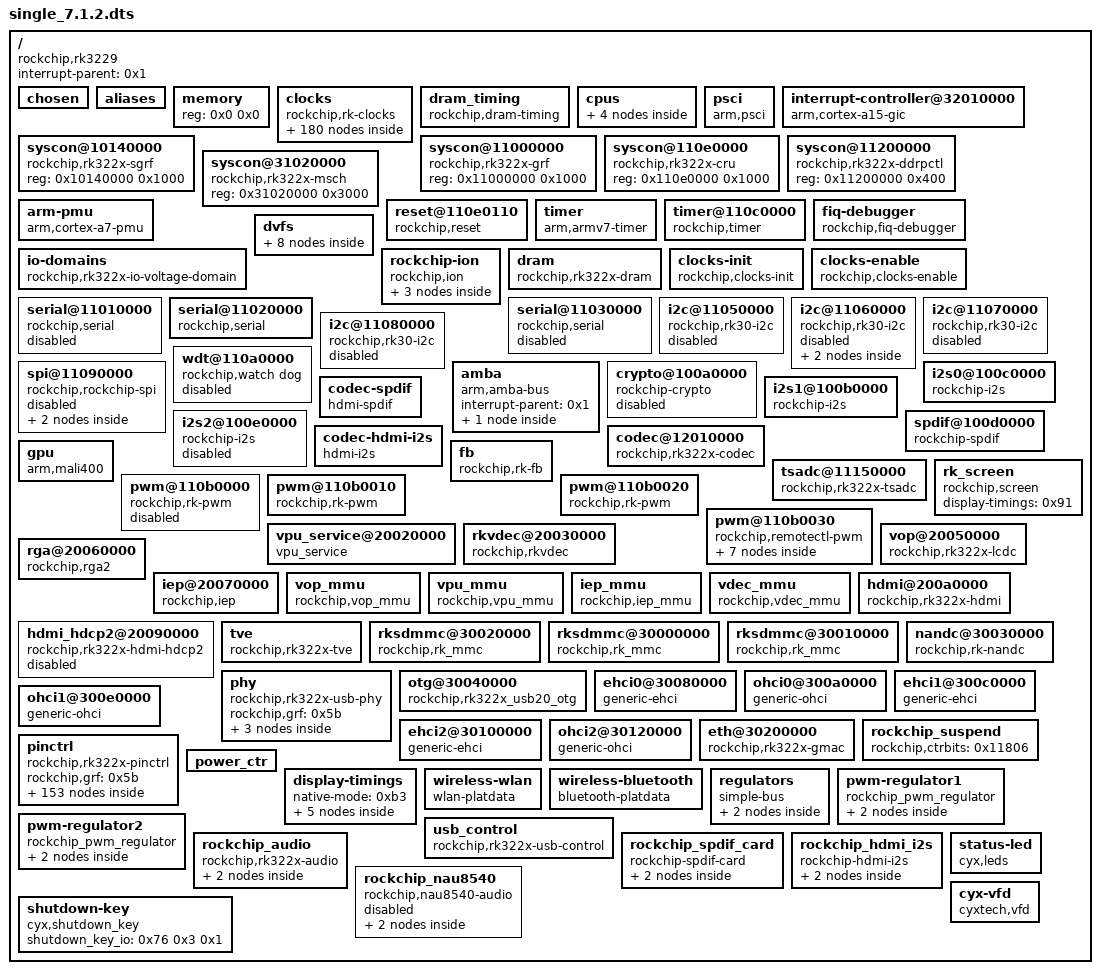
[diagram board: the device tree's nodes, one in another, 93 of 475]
/dts-v1/;

/ {
	#address-cells = <0x1>;
	#size-cells = <0x1>;
	compatible = "rockchip,rk3229";
	interrupt-parent = <0x1>;

	chosen {
		bootargs = "vmalloc=496M psci=enable rockchip_jtag";
	};

	aliases {
		serial0 = "/serial@11010000";
		serial1 = "/serial@11020000";
		serial2 = "/serial@11030000";
		i2c0 = "/i2c@11050000";
		i2c1 = "/i2c@11060000";
		i2c2 = "/i2c@11070000";
		i2c3 = "/i2c@11080000";
		lcdc0 = "/vop@20050000";
		spi0 = "/spi@11090000";
	};

	memory {
		device_type = "memory";
		reg = <0x0 0x0>;
	};

	clocks {
		compatible = "rockchip,rk-clocks";
		#address-cells = <0x1>;
		#size-cells = <0x1>;
		ranges = <0x0 0x110e0000 0x1000>;

		fixed_rate_cons {
			compatible = "rockchip,rk-fixed-rate-cons";

			xin24m {
				compatible = "rockchip,rk-fixed-clock";
				clock-output-names = "xin24m";
				clock-frequency = <0x16e3600>;
				#clock-cells = <0x0>;
				linux,phandle = <0x2>;
				phandle = <0x2>;
			};

			xin12m {
				compatible = "rockchip,rk-fixed-clock";
				clocks = <0x2>;
				clock-output-names = "xin12m";
				clock-frequency = <0xb71b00>;
				#clock-cells = <0x0>;
				linux,phandle = <0x14>;
				phandle = <0x14>;
			};

			hdmiphy_out {
				compatible = "rockchip,rk-fixed-clock";
				clock-output-names = "hdmiphy_out";
				clock-frequency = <0x2367b880>;
				#clock-cells = <0x0>;
				linux,phandle = <0x45>;
				phandle = <0x45>;
			};

			usbphy0_480m {
				compatible = "rockchip,rk-fixed-clock";
				clock-output-names = "usbphy0_480m";
				clock-frequency = <0x1c9c3800>;
				#clock-cells = <0x0>;
				linux,phandle = <0x46>;
				phandle = <0x46>;
			};

			usbphy1_480m {
				compatible = "rockchip,rk-fixed-clock";
				clock-output-names = "usbphy1_480m";
				clock-frequency = <0x1c9c3800>;
				#clock-cells = <0x0>;
				linux,phandle = <0x47>;
				phandle = <0x47>;
			};

			jtag_clkin {
				compatible = "rockchip,rk-fixed-clock";
				clock-output-names = "jtag_clkin";
				clock-frequency = <0x0>;
				#clock-cells = <0x0>;
				linux,phandle = <0x4c>;
				phandle = <0x4c>;
			};

			dummy {
				compatible = "rockchip,rk-fixed-clock";
				clock-output-names = "dummy";
				clock-frequency = <0x0>;
				#clock-cells = <0x0>;
				linux,phandle = <0x38>;
				phandle = <0x38>;
			};

			gmac_clkin {
				compatible = "rockchip,rk-fixed-clock";
				clock-output-names = "gmac_clkin";
				clock-frequency = <0x7735940>;
				#clock-cells = <0x0>;
				linux,phandle = <0x3c>;
				phandle = <0x3c>;
			};

			phy_50m_out {
				compatible = "rockchip,rk-fixed-clock";
				clock-output-names = "phy_50m_out";
				clock-frequency = <0x0>;
				#clock-cells = <0x0>;
				linux,phandle = <0x3d>;
				phandle = <0x3d>;
			};

			phy_rx_out {
				compatible = "rockchip,rk-fixed-clock";
				clock-output-names = "phy_rx_out";
				clock-frequency = <0x0>;
				#clock-cells = <0x0>;
			};

			phy_tx_out {
				compatible = "rockchip,rk-fixed-clock";
				clock-output-names = "phy_tx_out";
				clock-frequency = <0x0>;
				#clock-cells = <0x0>;
			};

			clkin_hsadc_tsp {
				compatible = "rockchip,rk-fixed-clock";
				clock-output-names = "clkin_hsadc_tsp";
				clock-frequency = <0x0>;
				#clock-cells = <0x0>;
				linux,phandle = <0x53>;
				phandle = <0x53>;
			};

			i2s_clkin {
				compatible = "rockchip,rk-fixed-clock";
				clock-output-names = "i2s_clkin";
				clock-frequency = <0x0>;
				#clock-cells = <0x0>;
				linux,phandle = <0x13>;
				phandle = <0x13>;
			};
		};

		fixed_factor_cons {
			compatible = "rockchip,rk-fixed-factor-cons";

			hclk_rkvdec {
				compatible = "rockchip,rk-fixed-factor-clock";
				clocks = <0x3>;
				clock-output-names = "hclk_rkvdec";
				clock-div = <0x4>;
				clock-mult = <0x1>;
				#clock-cells = <0x0>;
				linux,phandle = <0x58>;
				phandle = <0x58>;
			};

			hclk_vpu {
				compatible = "rockchip,rk-fixed-factor-clock";
				clocks = <0x4>;
				clock-output-names = "hclk_vpu";
				clock-div = <0x4>;
				clock-mult = <0x1>;
				#clock-cells = <0x0>;
				linux,phandle = <0x96>;
				phandle = <0x96>;
			};

			xin32k_out {
				compatible = "rockchip,rk-fixed-clock";
				clocks = <0x5>;
				clock-output-names = "xin32k_out";
				clock-div = <0x1>;
				clock-mult = <0x1>;
				#clock-cells = <0x0>;
			};
		};

		clock_regs {
			compatible = "rockchip,rk-clock-regs";
			#address-cells = <0x1>;
			#size-cells = <0x1>;
			reg = <0x0 0x1000>;
			ranges;

			pll_cons {
				compatible = "rockchip,rk-pll-cons";
				#address-cells = <0x1>;
				#size-cells = <0x1>;
				ranges;

				pll-clk@0000 {
					compatible = "rockchip,rk3188-pll-clk";
					reg = <0x0 0x10>;
					mode-reg = <0x40 0x0>;
					status-reg = <0x4 0xa>;
					clocks = <0x2>;
					clock-output-names = "clk_apll";
					rockchip,pll-type = <0x40>;
					#clock-cells = <0x0>;
					linux,phandle = <0x7>;
					phandle = <0x7>;
				};

				pll-clk@000c {
					compatible = "rockchip,rk3188-pll-clk";
					reg = <0xc 0x10>;
					mode-reg = <0x40 0x4>;
					status-reg = <0x10 0xa>;
					clocks = <0x2>;
					clock-output-names = "clk_dpll";
					rockchip,pll-type = <0x80>;
					#clock-cells = <0x0>;
					linux,phandle = <0x9>;
					phandle = <0x9>;
				};

				pll-clk@0018 {
					compatible = "rockchip,rk3188-pll-clk";
					reg = <0x18 0x10>;
					mode-reg = <0x40 0x8>;
					status-reg = <0x1c 0xa>;
					clocks = <0x2>;
					clock-output-names = "clk_cpll";
					rockchip,pll-type = <0x100>;
					#clock-cells = <0x0>;
					#clock-init-cells = <0x1>;
					linux,phandle = <0xb>;
					phandle = <0xb>;
				};

				pll-clk@0024 {
					compatible = "rockchip,rk3188-pll-clk";
					reg = <0x24 0x10>;
					mode-reg = <0x40 0xc>;
					status-reg = <0x28 0xa>;
					clocks = <0x2>;
					clock-output-names = "clk_gpll";
					rockchip,pll-type = <0x100>;
					#clock-cells = <0x0>;
					#clock-init-cells = <0x1>;
					linux,phandle = <0x8>;
					phandle = <0x8>;
				};
			};

			clk_sel_cons {
				compatible = "rockchip,rk-sel-cons";
				#address-cells = <0x1>;
				#size-cells = <0x1>;
				ranges;

				sel-con@0044 {
					compatible = "rockchip,rk3188-selcon";
					reg = <0x44 0x4>;
					#address-cells = <0x1>;
					#size-cells = <0x1>;

					clk_core_div {
						compatible = "rockchip,rk3188-div-con";
						rockchip,bits = <0x0 0x5>;
						clocks = <0x6>;
						clock-output-names = "clk_core";
						rockchip,div-type = <0x0>;
						#clock-cells = <0x0>;
						rockchip,clkops-idx = <0xb>;
						rockchip,flags = <0xc0>;
					};

					clk_core_mux {
						compatible = "rockchip,rk3188-mux-con";
						rockchip,bits = <0x6 0x2>;
						clocks = <0x7 0x8 0x9>;
						clock-output-names = "clk_core";
						#clock-cells = <0x0>;
						#clock-init-cells = <0x1>;
						linux,phandle = <0x6>;
						phandle = <0x6>;
					};

					aclk_bus_div {
						compatible = "rockchip,rk3188-div-con";
						rockchip,bits = <0x8 0x5>;
						clocks = <0xa>;
						clock-output-names = "aclk_bus";
						rockchip,div-type = <0x0>;
						#clock-cells = <0x0>;
						#clock-init-cells = <0x1>;
						rockchip,clkops-idx = <0x1>;
						rockchip,flags = <0x100>;
						linux,phandle = <0xd>;
						phandle = <0xd>;
					};

					aclk_bus_mux {
						compatible = "rockchip,rk3188-mux-con";
						rockchip,bits = <0xd 0x2>;
						clocks = <0xb 0x8 0xc>;
						clock-output-names = "aclk_bus";
						#clock-cells = <0x0>;
						#clock-init-cells = <0x1>;
						linux,phandle = <0xa>;
						phandle = <0xa>;
					};
				};

				sel-con@0048 {
					compatible = "rockchip,rk3188-selcon";
					reg = <0x48 0x4>;
					#address-cells = <0x1>;
					#size-cells = <0x1>;

					pclk_dbg_div {
						compatible = "rockchip,rk3188-div-con";
						rockchip,bits = <0x0 0x4>;
						clocks = <0x6>;
						clock-output-names = "pclk_dbg";
						rockchip,div-type = <0x0>;
						#clock-cells = <0x0>;
						rockchip,clkops-idx = <0xc>;
						linux,phandle = <0x60>;
						phandle = <0x60>;
					};

					aclk_core_div {
						compatible = "rockchip,rk3188-div-con";
						rockchip,bits = <0x4 0x3>;
						clocks = <0x6>;
						clock-output-names = "aclk_core";
						rockchip,div-type = <0x0>;
						#clock-cells = <0x0>;
						rockchip,clkops-idx = <0xc>;
						linux,phandle = <0x44>;
						phandle = <0x44>;
					};

					hclk_bus_div {
						compatible = "rockchip,rk3188-div-con";
						rockchip,bits = <0x8 0x2>;
						clocks = <0xd>;
						clock-output-names = "hclk_bus";
						rockchip,div-type = <0x0>;
						#clock-cells = <0x0>;
						#clock-init-cells = <0x1>;
						linux,phandle = <0x51>;
						phandle = <0x51>;
					};

					pclk_bus_div {
						compatible = "rockchip,rk3188-div-con";
						rockchip,bits = <0xc 0x3>;
						clocks = <0xd>;
						clock-output-names = "pclk_bus";
						rockchip,div-type = <0x0>;
						#clock-cells = <0x0>;
						#clock-init-cells = <0x1>;
						linux,phandle = <0x4f>;
						phandle = <0x4f>;
					};
				};

				sel-con@004c {
					compatible = "rockchip,rk3188-selcon";
					reg = <0x4c 0x4>;
					#address-cells = <0x1>;
					#size-cells = <0x1>;

					hclk_vio_div {
						compatible = "rockchip,rk3188-div-con";
						rockchip,bits = <0x0 0x5>;
						clocks = <0xe>;
						clock-output-names = "hclk_vio";
						rockchip,div-type = <0x0>;
						#clock-cells = <0x0>;
						#clock-init-cells = <0x1>;
						linux,phandle = <0x57>;
						phandle = <0x57>;
					};

					clk_nandc_div {
						compatible = "rockchip,rk3188-div-con";
						rockchip,bits = <0x8 0x5>;
						clocks = <0xf>;
						clock-output-names = "clk_nandc";
						rockchip,div-type = <0x0>;
						#clock-cells = <0x0>;
						rockchip,clkops-idx = <0x1>;
						rockchip,flags = <0x100>;
					};

					clk_nandc_mux {
						compatible = "rockchip,rk3188-mux-con";
						rockchip,bits = <0xe 0x1>;
						clocks = <0xb 0x8>;
						clock-output-names = "clk_nandc";
						#clock-cells = <0x0>;
						#clock-init-cells = <0x1>;
						linux,phandle = <0xf>;
						phandle = <0xf>;
					};
				};

				sel-con@0050 {
					compatible = "rockchip,rk3188-selcon";
					reg = <0x50 0x4>;
					#address-cells = <0x1>;
					#size-cells = <0x1>;

					clk_i2s1_pll_div {
						compatible = "rockchip,rk3188-div-con";
						rockchip,bits = <0x0 0x7>;
						clocks = <0x10>;
						clock-output-names = "clk_i2s1_pll";
						rockchip,div-type = <0x0>;
						#clock-cells = <0x0>;
						rockchip,clkops-idx = <0x1>;
						rockchip,flags = <0x180>;
						linux,phandle = <0x11>;
						phandle = <0x11>;
					};

					clk_i2s1_mux {
						compatible = "rockchip,rk3188-mux-con";
						rockchip,bits = <0x8 0x2>;
						clocks = <0x11 0x12 0x13 0x14>;
						clock-output-names = "clk_i2s1";
						#clock-cells = <0x0>;
						rockchip,clkops-idx = <0xe>;
						rockchip,flags = <0x4>;
						linux,phandle = <0x15>;
						phandle = <0x15>;
					};

					clk_i2s1_out_mux {
						compatible = "rockchip,rk3188-mux-con";
						rockchip,bits = <0xc 0x1>;
						clocks = <0x15 0x14>;
						clock-output-names = "clk_i2s1_out";
						#clock-cells = <0x0>;
						linux,phandle = <0x4b>;
						phandle = <0x4b>;
					};

					i2s1_pll_mux {
						compatible = "rockchip,rk3188-mux-con";
						rockchip,bits = <0xf 0x1>;
						clocks = <0xb 0x8>;
						clock-output-names = "clk_i2s1_pll";
						#clock-cells = <0x0>;
						#clock-init-cells = <0x1>;
						linux,phandle = <0x10>;
						phandle = <0x10>;
					};
				};

				sel-con@0054 {
					compatible = "rockchip,rk3188-selcon";
					reg = <0x54 0x4>;
					#address-cells = <0x1>;
					#size-cells = <0x1>;

					testclk_div {
						compatible = "rockchip,rk3188-div-con";
						rockchip,bits = <0x0 0x5>;
						clocks = <0x16>;
						clock-output-names = "testclk";
						rockchip,div-type = <0x0>;
						#clock-cells = <0x0>;
						rockchip,clkops-idx = <0x1>;
					};

					clk_24m_div {
						compatible = "rockchip,rk3188-div-con";
						rockchip,bits = <0x8 0x5>;
						clocks = <0x2>;
						clock-output-names = "clk_24m";
						rockchip,div-type = <0x0>;
						#clock-cells = <0x0>;
						rockchip,clkops-idx = <0x1>;
					};
				};

				sel-con@0058 {
					compatible = "rockchip,rk3188-selcon";
					reg = <0x58 0x4>;
					#address-cells = <0x1>;
					#size-cells = <0x1>;

					clk_mac_pll_div {
						compatible = "rockchip,rk3188-div-con";
						rockchip,bits = <0x0 0x5>;
						clocks = <0x17>;
						clock-output-names = "clk_mac_pll";
						rockchip,div-type = <0x0>;
						#clock-cells = <0x0>;
						rockchip,clkops-idx = <0x1>;
						rockchip,flags = <0x100>;
						linux,phandle = <0x3e>;
						phandle = <0x3e>;
					};

					clk_mac_mux {
						compatible = "rockchip,rk3188-mux-con";
						rockchip,bits = <0x5 0x1>;
						clocks = <0x17 0x18>;
						clock-output-names = "clk_mac";
						#clock-cells = <0x0>;
						rockchip,flags = <0x4>;
						#clock-init-cells = <0x1>;
						linux,phandle = <0x4e>;
						phandle = <0x4e>;
					};

					clk_mac_pll_mux {
						compatible = "rockchip,rk3188-mux-con";
						rockchip,bits = <0x7 0x1>;
						clocks = <0xb 0x8>;
						clock-output-names = "clk_mac_pll";
						#clock-cells = <0x0>;
						linux,phandle = <0x17>;
						phandle = <0x17>;
					};

					clk_gmac_div {
						compatible = "rockchip,rk3188-div-con";
						rockchip,bits = <0x8 0x5>;
						clocks = <0x19>;
						clock-output-names = "clk_gmac";
						rockchip,div-type = <0x0>;
						#clock-cells = <0x0>;
						rockchip,clkops-idx = <0x1>;
						rockchip,flags = <0x100>;
					};

					clk_gmac_mux {
						compatible = "rockchip,rk3188-mux-con";
						rockchip,bits = <0xf 0x1>;
						clocks = <0xb 0x8>;
						clock-output-names = "clk_gmac";
						#clock-cells = <0x0>;
						#clock-init-cells = <0x1>;
						linux,phandle = <0x19>;
						phandle = <0x19>;
					};
				};

				sel-con@005c {
					compatible = "rockchip,rk3188-selcon";
					reg = <0x5c 0x4>;
					#address-cells = <0x1>;
					#size-cells = <0x1>;

					spdif_div {
						compatible = "rockchip,rk3188-div-con";
						rockchip,bits = <0x0 0x7>;
						clocks = <0x1a>;
						clock-output-names = "clk_spdif_pll";
						rockchip,div-type = <0x0>;
						#clock-cells = <0x0>;
						rockchip,clkops-idx = <0x1>;
						rockchip,flags = <0x180>;
						linux,phandle = <0x1b>;
						phandle = <0x1b>;
					};

					spdif_mux {
						compatible = "rockchip,rk3188-mux-con";
						rockchip,bits = <0x8 0x2>;
						clocks = <0x1b 0x1c 0x14>;
						clock-output-names = "clk_spdif";
						#clock-cells = <0x0>;
						rockchip,clkops-idx = <0xe>;
						rockchip,flags = <0x4>;
						linux,phandle = <0x8c>;
						phandle = <0x8c>;
					};

					spdif_pll_mux {
						compatible = "rockchip,rk3188-mux-con";
						rockchip,bits = <0xf 0x1>;
						clocks = <0xb 0x8>;
						clock-output-names = "clk_spdif_pll";
						#clock-cells = <0x0>;
						#clock-init-cells = <0x1>;
						linux,phandle = <0x1a>;
						phandle = <0x1a>;
					};
				};

				sel-con@0060 {
					compatible = "rockchip,rk3188-selcon";
					reg = <0x60 0x4>;
					#address-cells = <0x1>;
					#size-cells = <0x1>;

					i2s1_frac {
						compatible = "rockchip,rk3188-frac-con";
						clocks = <0x11>;
						clock-output-names = "i2s1_frac";
						rockchip,bits = <0x0 0x20>;
						rockchip,clkops-idx = <0x5>;
						#clock-cells = <0x0>;
						linux,phandle = <0x12>;
						phandle = <0x12>;
					};
				};

				sel-con@0064 {
					compatible = "rockchip,rk3188-selcon";
					reg = <0x64 0x4>;
					#address-cells = <0x1>;
					#size-cells = <0x1>;

					i2s0_frac {
						compatible = "rockchip,rk3188-frac-con";
						clocks = <0x1d>;
						clock-output-names = "i2s0_frac";
						rockchip,bits = <0x0 0x20>;
						rockchip,clkops-idx = <0x5>;
						#clock-cells = <0x0>;
						linux,phandle = <0x1f>;
						phandle = <0x1f>;
					};
				};

				sel-con@0068 {
					compatible = "rockchip,rk3188-selcon";
					reg = <0x68 0x4>;
					#address-cells = <0x1>;
					#size-cells = <0x1>;

					clk_i2s0_pll_div {
						compatible = "rockchip,rk3188-div-con";
						rockchip,bits = <0x0 0x7>;
						clocks = <0x1e>;
						clock-output-names = "clk_i2s0_pll";
						rockchip,div-type = <0x0>;
						#clock-cells = <0x0>;
						rockchip,clkops-idx = <0x1>;
						rockchip,flags = <0x180>;
						linux,phandle = <0x1d>;
						phandle = <0x1d>;
					};

					clk_i2s0_mux {
						compatible = "rockchip,rk3188-mux-con";
						rockchip,bits = <0x8 0x2>;
						clocks = <0x1d 0x1f 0x13 0x14>;
						clock-output-names = "clk_i2s0";
						#clock-cells = <0x0>;
						rockchip,clkops-idx = <0xe>;
						rockchip,flags = <0x4>;
						linux,phandle = <0x49>;
						phandle = <0x49>;
					};

					i2s0_pll_mux {
						compatible = "rockchip,rk3188-mux-con";
						rockchip,bits = <0xf 0x1>;
						clocks = <0xb 0x8>;
						clock-output-names = "clk_i2s0_pll";
						#clock-cells = <0x0>;
						#clock-init-cells = <0x1>;
						linux,phandle = <0x1e>;
						phandle = <0x1e>;
					};
				};

				sel-con@006c {
					compatible = "rockchip,rk3188-selcon";
					reg = <0x6c 0x4>;
					#address-cells = <0x1>;
					#size-cells = <0x1>;

					aclk_peri_div {
						compatible = "rockchip,rk3188-div-con";
						rockchip,bits = <0x0 0x5>;
						clocks = <0x20>;
						clock-output-names = "aclk_peri";
						rockchip,div-type = <0x0>;
						#clock-cells = <0x0>;
						rockchip,clkops-idx = <0x1>;
						rockchip,flags = <0x100>;
					};

					hclk_peri_div {
						compatible = "rockchip,rk3188-div-con";
						rockchip,bits = <0x8 0x2>;
						clocks = <0x20>;
						clock-output-names = "hclk_peri";
						rockchip,div-type = <0x80>;
						rockchip,div-relations = <0x0 0x1 0x1 0x2 0x2 0x4>;
						#clock-cells = <0x0>;
						#clock-init-cells = <0x1>;
						linux,phandle = <0x54>;
						phandle = <0x54>;
					};

					aclk_peri_mux {
						compatible = "rockchip,rk3188-mux-con";
						rockchip,bits = <0xa 0x2>;
						clocks = <0xb 0x8 0xc>;
						clock-output-names = "aclk_peri";
						#clock-cells = <0x0>;
						#clock-init-cells = <0x1>;
						linux,phandle = <0x20>;
						phandle = <0x20>;
					};

					pclk_peri_div {
						compatible = "rockchip,rk3188-div-con";
						rockchip,bits = <0xc 0x2>;
						clocks = <0x20>;
						clock-output-names = "pclk_peri";
						rockchip,div-type = <0x80>;
						rockchip,div-relations = <0x0 0x1 0x1 0x2 0x2 0x4 0x3 0x8>;
						#clock-cells = <0x0>;
						#clock-init-cells = <0x1>;
						linux,phandle = <0x55>;
						phandle = <0x55>;
					};
				};

				sel-con@0070 {
					compatible = "rockchip,rk3188-selcon";
					reg = <0x70 0x4>;
					#address-cells = <0x1>;
					#size-cells = <0x1>;

					clk_sdmmc0_div {
						compatible = "rockchip,rk3188-div-con";
						rockchip,bits = <0x0 0x8>;
						clocks = <0x21>;
						clock-output-names = "clk_sdmmc0";
						rockchip,div-type = <0x0>;
						#clock-cells = <0x0>;
						rockchip,clkops-idx = <0x3>;
						rockchip,flags = <0x100>;
					};

					clk_sdmmc0_mux {
						compatible = "rockchip,rk3188-mux-con";
						rockchip,bits = <0x8 0x2>;
						clocks = <0xb 0x8 0x2 0x22>;
						clock-output-names = "clk_sdmmc0";
						#clock-cells = <0x0>;
						#clock-init-cells = <0x1>;
						linux,phandle = <0x21>;
						phandle = <0x21>;
					};

					clk_sdio_mux {
						compatible = "rockchip,rk3188-mux-con";
						rockchip,bits = <0xa 0x2>;
						clocks = <0xb 0x8 0x2 0x22>;
						clock-output-names = "clk_sdio";
						#clock-cells = <0x0>;
						#clock-init-cells = <0x1>;
						linux,phandle = <0x23>;
						phandle = <0x23>;
					};

					clk_emmc_mux {
						compatible = "rockchip,rk3188-mux-con";
						rockchip,bits = <0xc 0x2>;
						clocks = <0xb 0x8 0x2 0x22>;
						clock-output-names = "clk_emmc";
						#clock-cells = <0x0>;
						#clock-init-cells = <0x1>;
						linux,phandle = <0x24>;
						phandle = <0x24>;
					};
				};

				sel-con@0074 {
					compatible = "rockchip,rk3188-selcon";
					reg = <0x74 0x4>;
					#address-cells = <0x1>;
					#size-cells = <0x1>;

					clk_sdio_div {
						compatible = "rockchip,rk3188-div-con";
						rockchip,bits = <0x0 0x8>;
						clocks = <0x23>;
						clock-output-names = "clk_sdio";
						rockchip,div-type = <0x0>;
						#clock-cells = <0x0>;
						rockchip,clkops-idx = <0x3>;
						rockchip,flags = <0x100>;
					};

					clk_emmc_div {
						compatible = "rockchip,rk3188-div-con";
						rockchip,bits = <0x8 0x8>;
						clocks = <0x24>;
						clock-output-names = "clk_emmc";
						rockchip,div-type = <0x0>;
						#clock-cells = <0x0>;
						rockchip,clkops-idx = <0x3>;
						rockchip,flags = <0x100>;
					};
				};

				sel-con@0078 {
					compatible = "rockchip,rk3188-selcon";
					reg = <0x78 0x4>;
					#address-cells = <0x1>;
					#size-cells = <0x1>;

					clk_uart0_pll_div {
						compatible = "rockchip,rk3188-div-con";
						rockchip,bits = <0x0 0x7>;
						clocks = <0x25>;
						clock-output-names = "clk_uart0_pll";
						rockchip,div-type = <0x0>;
						#clock-cells = <0x0>;
						rockchip,flags = <0x100>;
						linux,phandle = <0x26>;
						phandle = <0x26>;
					};

					clk_uart0_mux {
						compatible = "rockchip,rk3188-mux-con";
						rockchip,bits = <0x8 0x2>;
						clocks = <0x26 0x27 0x2>;
						clock-output-names = "clk_uart0";
						#clock-cells = <0x0>;
						rockchip,clkops-idx = <0xe>;
						rockchip,flags = <0x4>;
						linux,phandle = <0x69>;
						phandle = <0x69>;
					};

					clk_uart0_pll_mux {
						compatible = "rockchip,rk3188-mux-con";
						rockchip,bits = <0xc 0x2>;
						clocks = <0xb 0x8 0x22>;
						clock-output-names = "clk_uart0_pll";
						#clock-cells = <0x0>;
						#clock-init-cells = <0x1>;
						linux,phandle = <0x25>;
						phandle = <0x25>;
					};
				};

				sel-con@007c {
					compatible = "rockchip,rk3188-selcon";
					reg = <0x7c 0x4>;
					#address-cells = <0x1>;
					#size-cells = <0x1>;

					clk_uart1_pll_div {
						compatible = "rockchip,rk3188-div-con";
						rockchip,bits = <0x0 0x7>;
						clocks = <0x28>;
						clock-output-names = "clk_uart1_pll";
						rockchip,div-type = <0x0>;
						#clock-cells = <0x0>;
						rockchip,flags = <0x100>;
						linux,phandle = <0x29>;
						phandle = <0x29>;
					};

					clk_uart1_mux {
						compatible = "rockchip,rk3188-mux-con";
						rockchip,bits = <0x8 0x2>;
						clocks = <0x29 0x2a 0x2>;
						clock-output-names = "clk_uart1";
						#clock-cells = <0x0>;
						rockchip,clkops-idx = <0xe>;
						rockchip,flags = <0x4>;
						linux,phandle = <0x6e>;
						phandle = <0x6e>;
					};

					clk_uart1_pll_mux {
						compatible = "rockchip,rk3188-mux-con";
						rockchip,bits = <0xc 0x2>;
						clocks = <0xb 0x8 0x22>;
						clock-output-names = "clk_uart1_pll";
						#clock-cells = <0x0>;
						#clock-init-cells = <0x1>;
						linux,phandle = <0x28>;
						phandle = <0x28>;
					};
				};

				sel-con@0080 {
					compatible = "rockchip,rk3188-selcon";
					reg = <0x80 0x4>;
					#address-cells = <0x1>;
					#size-cells = <0x1>;

					clk_uart2_pll_div {
						compatible = "rockchip,rk3188-div-con";
						rockchip,bits = <0x0 0x7>;
						clocks = <0x2b>;
						clock-output-names = "clk_uart2_pll";
						rockchip,div-type = <0x0>;
						#clock-cells = <0x0>;
						rockchip,flags = <0x100>;
						linux,phandle = <0x30>;
						phandle = <0x30>;
					};

					clk_uart2_mux {
						compatible = "rockchip,rk3188-mux-con";
						rockchip,bits = <0x8 0x2>;
						clocks = <0x2b 0x2c 0x2>;
						clock-output-names = "clk_uart2";
						#clock-cells = <0x0>;
						rockchip,clkops-idx = <0xe>;
						rockchip,flags = <0x4>;
						linux,phandle = <0x72>;
						phandle = <0x72>;
					};

					clk_uart2_pll_mux {
						compatible = "rockchip,rk3188-mux-con";
						rockchip,bits = <0xc 0x2>;
						clocks = <0xb 0x8 0x22>;
						clock-output-names = "clk_uart2_pll";
						#clock-cells = <0x0>;
						#clock-init-cells = <0x1>;
						linux,phandle = <0x2b>;
						phandle = <0x2b>;
					};
				};

				sel-con@0084 {
					compatible = "rockchip,rk3188-selcon";
					reg = <0x84 0x4>;
					#address-cells = <0x1>;
					#size-cells = <0x1>;

					i2s2_pll_div {
						compatible = "rockchip,rk3188-div-con";
						rockchip,bits = <0x0 0x7>;
						clocks = <0x2d>;
						clock-output-names = "clk_i2s2_pll";
						rockchip,div-type = <0x0>;
						#clock-cells = <0x0>;
						rockchip,clkops-idx = <0x1>;
						rockchip,flags = <0x180>;
						linux,phandle = <0x2e>;
						phandle = <0x2e>;
					};

					clk_i2s2_mux {
						compatible = "rockchip,rk3188-mux-con";
						rockchip,bits = <0x8 0x2>;
						clocks = <0x2e 0x2f 0x13 0x14>;
						clock-output-names = "clk_i2s2";
						#clock-cells = <0x0>;
						rockchip,clkops-idx = <0xe>;
						rockchip,flags = <0x4>;
						linux,phandle = <0x4a>;
						phandle = <0x4a>;
					};

					i2s2_pll_mux {
						compatible = "rockchip,rk3188-mux-con";
						rockchip,bits = <0xf 0x1>;
						clocks = <0xb 0x8>;
						clock-output-names = "clk_i2s2_pll";
						#clock-cells = <0x0>;
						#clock-init-cells = <0x1>;
						linux,phandle = <0x2d>;
						phandle = <0x2d>;
					};
				};

				sel-con@0088 {
					compatible = "rockchip,rk3188-selcon";
					reg = <0x88 0x4>;
					#address-cells = <0x1>;
					#size-cells = <0x1>;

					uart0_frac {
						compatible = "rockchip,rk3188-frac-con";
						clocks = <0x26>;
						clock-output-names = "uart0_frac";
						rockchip,bits = <0x0 0x20>;
						rockchip,clkops-idx = <0x5>;
						#clock-cells = <0x0>;
						linux,phandle = <0x27>;
						phandle = <0x27>;
					};
				};

				sel-con@008c {
					compatible = "rockchip,rk3188-selcon";
					reg = <0x8c 0x4>;
					#address-cells = <0x1>;
					#size-cells = <0x1>;

					uart1_frac {
						compatible = "rockchip,rk3188-frac-con";
						clocks = <0x29>;
						clock-output-names = "uart1_frac";
						rockchip,bits = <0x0 0x20>;
						rockchip,clkops-idx = <0x5>;
						#clock-cells = <0x0>;
						linux,phandle = <0x2a>;
						phandle = <0x2a>;
					};
				};

				sel-con@0090 {
					compatible = "rockchip,rk3188-selcon";
					reg = <0x90 0x4>;
					#address-cells = <0x1>;
					#size-cells = <0x1>;

					uart2_frac {
						compatible = "rockchip,rk3188-frac-con";
						clocks = <0x30>;
						clock-output-names = "uart2_frac";
						rockchip,bits = <0x0 0x20>;
						rockchip,clkops-idx = <0x5>;
						#clock-cells = <0x0>;
						linux,phandle = <0x2c>;
						phandle = <0x2c>;
					};
				};

				sel-con@0094 {
					compatible = "rockchip,rk3188-selcon";
					reg = <0x94 0x4>;
					#address-cells = <0x1>;
					#size-cells = <0x1>;

					spdif_frac {
						compatible = "rockchip,rk3188-frac-con";
						clocks = <0x1b>;
						clock-output-names = "spdif_frac";
						rockchip,bits = <0x0 0x20>;
						rockchip,clkops-idx = <0x5>;
						#clock-cells = <0x0>;
						linux,phandle = <0x1c>;
						phandle = <0x1c>;
					};
				};

				sel-con@0098 {
					compatible = "rockchip,rk3188-selcon";
					reg = <0x98 0x4>;
					#address-cells = <0x1>;
					#size-cells = <0x1>;

					clk_hdmi_cec_div {
						compatible = "rockchip,rk3188-div-con";
						rockchip,bits = <0x0 0xe>;
						clocks = <0x5>;
						clock-output-names = "clk_hdmi_cec";
						rockchip,div-type = <0x0>;
						#clock-cells = <0x0>;
						rockchip,clkops-idx = <0x1>;
						rockchip,flags = <0x100>;
						#clock-init-cells = <0x1>;
						linux,phandle = <0x5>;
						phandle = <0x5>;
					};

					clk_hdmi_cec_mux {
						compatible = "rockchip,rk3188-mux-con";
						rockchip,bits = <0xe 0x2>;
						clocks = <0xb 0x8 0x2>;
						clock-output-names = "clk_hdmi_cec";
						#clock-cells = <0x0>;
						#clock-init-cells = <0x1>;
					};
				};

				sel-con@009c {
					compatible = "rockchip,rk3188-selcon";
					reg = <0x9c 0x4>;
					#address-cells = <0x1>;
					#size-cells = <0x1>;

					clk_rga_div {
						compatible = "rockchip,rk3188-div-con";
						rockchip,bits = <0x0 0x5>;
						clocks = <0x31>;
						clock-output-names = "clk_rga";
						rockchip,div-type = <0x0>;
						#clock-cells = <0x0>;
						rockchip,clkops-idx = <0x1>;
						rockchip,flags = <0x100>;
					};

					clk_tsp_div {
						compatible = "rockchip,rk3188-div-con";
						rockchip,bits = <0x8 0x5>;
						clocks = <0x32>;
						clock-output-names = "clk_tsp";
						rockchip,div-type = <0x0>;
						#clock-cells = <0x0>;
						rockchip,clkops-idx = <0x1>;
						rockchip,flags = <0x100>;
					};

					clk_tsp_mux {
						compatible = "rockchip,rk3188-mux-con";
						rockchip,bits = <0xf 0x1>;
						clocks = <0xb 0x8>;
						clock-output-names = "clk_tsp";
						#clock-cells = <0x0>;
						linux,phandle = <0x32>;
						phandle = <0x32>;
					};
				};

				sel-con@00a0 {
					compatible = "rockchip,rk3188-selcon";
					reg = <0xa0 0x4>;
					#address-cells = <0x1>;
					#size-cells = <0x1>;

					clk_wifi_div {
						compatible = "rockchip,rk3188-div-con";
						rockchip,bits = <0x0 0x5>;
						clocks = <0x33>;
						clock-output-names = "clk_wifi";
						rockchip,div-type = <0x0>;
						#clock-cells = <0x0>;
						rockchip,clkops-idx = <0x1>;
						rockchip,flags = <0x100>;
					};

					clk_wifi_mux {
						compatible = "rockchip,rk3188-mux-con";
						rockchip,bits = <0x5 0x2>;
						clocks = <0xb 0x8 0x22>;
						clock-output-names = "clk_wifi";
						#clock-cells = <0x0>;
						linux,phandle = <0x33>;
						phandle = <0x33>;
					};

					clk_hdcp_div {
						compatible = "rockchip,rk3188-div-con";
						rockchip,bits = <0x8 0x6>;
						clocks = <0x34>;
						clock-output-names = "clk_hdcp";
						rockchip,div-type = <0x0>;
						#clock-cells = <0x0>;
						rockchip,clkops-idx = <0x1>;
						rockchip,flags = <0x100>;
					};

					clk_hdcp_mux {
						compatible = "rockchip,rk3188-mux-con";
						rockchip,bits = <0xe 0x2>;
						clocks = <0xb 0x8 0xc>;
						clock-output-names = "clk_hdcp";
						#clock-cells = <0x0>;
						linux,phandle = <0x34>;
						phandle = <0x34>;
					};
				};

				sel-con@00a4 {
					compatible = "rockchip,rk3188-selcon";
					reg = <0xa4 0x4>;
					#address-cells = <0x1>;
					#size-cells = <0x1>;

					clk_crypto_div {
						compatible = "rockchip,rk3188-div-con";
						rockchip,bits = <0x0 0x5>;
						clocks = <0x35>;
						clock-output-names = "clk_crypto";
						rockchip,div-type = <0x0>;
						#clock-cells = <0x0>;
						#clock-init-cells = <0x1>;
						rockchip,flags = <0x100>;
					};

					clk_crypto_mux {
						compatible = "rockchip,rk3188-mux-con";
						rockchip,bits = <0x5 0x1>;
						clocks = <0xb 0x8>;
						clock-output-names = "clk_crypto";
						#clock-cells = <0x0>;
						linux,phandle = <0x35>;
						phandle = <0x35>;
					};

					clk_tsadc_div {
						compatible = "rockchip,rk3188-div-con";
						rockchip,bits = <0x6 0xa>;
						clocks = <0x2>;
						clock-output-names = "clk_tsadc";
						rockchip,div-type = <0x0>;
						#clock-cells = <0x0>;
						#clock-init-cells = <0x1>;
						linux,phandle = <0x4d>;
						phandle = <0x4d>;
					};
				};

				sel-con@00a8 {
					compatible = "rockchip,rk3188-selcon";
					reg = <0xa8 0x4>;
					#address-cells = <0x1>;
					#size-cells = <0x1>;

					clk_spi0_div {
						compatible = "rockchip,rk3188-div-con";
						rockchip,bits = <0x0 0x7>;
						clocks = <0x36>;
						clock-output-names = "clk_spi0";
						rockchip,div-type = <0x0>;
						#clock-cells = <0x0>;
						rockchip,clkops-idx = <0x1>;
						rockchip,flags = <0x100>;
					};

					clk_spi0_mux {
						compatible = "rockchip,rk3188-mux-con";
						rockchip,bits = <0x8 0x1>;
						clocks = <0xb 0x8>;
						clock-output-names = "clk_spi0";
						#clock-cells = <0x0>;
						linux,phandle = <0x36>;
						phandle = <0x36>;
					};
				};

				sel-con@00ac {
					compatible = "rockchip,rk3188-selcon";
					reg = <0xac 0x4>;
					#address-cells = <0x1>;
					#size-cells = <0x1>;

					clk_ddr_div {
						compatible = "rockchip,rk3188-div-con";
						rockchip,bits = <0x0 0x2>;
						clocks = <0x37>;
						clock-output-names = "clk_ddr";
						rockchip,div-type = <0x80>;
						rockchip,div-relations = <0x0 0x1 0x1 0x2 0x3 0x4>;
						#clock-cells = <0x0>;
						rockchip,flags = <0xc0>;
						rockchip,clkops-idx = <0x12>;
						linux,phandle = <0x50>;
						phandle = <0x50>;
					};

					clk_ddr_pll_mux {
						compatible = "rockchip,rk3188-mux-con";
						rockchip,bits = <0x8 0x2>;
						clocks = <0x9 0x8 0x7>;
						clock-output-names = "clk_ddr";
						#clock-cells = <0x0>;
						linux,phandle = <0x37>;
						phandle = <0x37>;
					};
				};

				sel-con@00b0 {
					compatible = "rockchip,rk3188-selcon";
					reg = <0xb0 0x4>;
					#address-cells = <0x1>;
					#size-cells = <0x1>;

					dclk_vop0_pll_mux {
						compatible = "rockchip,rk3188-mux-con";
						rockchip,bits = <0x0 0x1>;
						clocks = <0x8 0xb>;
						clock-output-names = "dclk_vop0_pll";
						#clock-cells = <0x0>;
						#clock-init-cells = <0x1>;
						linux,phandle = <0x39>;
						phandle = <0x39>;
					};

					dclk_vop0_mux {
						compatible = "rockchip,rk3188-mux-con";
						rockchip,bits = <0x1 0x1>;
						clocks = <0xc 0x38>;
						clock-output-names = "dclk_vop0";
						#clock-cells = <0x0>;
						#clock-init-cells = <0x1>;
						linux,phandle = <0x5f>;
						phandle = <0x5f>;
					};

					dclk_vop0_div {
						compatible = "rockchip,rk3188-div-con";
						rockchip,bits = <0x8 0x8>;
						clocks = <0x39>;
						clock-output-names = "dclk_vop0";
						rockchip,div-type = <0x0>;
						#clock-cells = <0x0>;
						rockchip,clkops-idx = <0x1>;
					};
				};

				sel-con@00b4 {
					compatible = "rockchip,rk3188-selcon";
					reg = <0xb4 0x4>;
					#address-cells = <0x1>;
					#size-cells = <0x1>;

					aclk_rkvdec_div {
						compatible = "rockchip,rk3188-div-con";
						rockchip,bits = <0x0 0x5>;
						clocks = <0x3>;
						clock-output-names = "aclk_rkvdec";
						rockchip,div-type = <0x0>;
						#clock-cells = <0x0>;
						rockchip,clkops-idx = <0x1>;
						rockchip,flags = <0x100>;
					};

					aclk_rkvdec_mux {
						compatible = "rockchip,rk3188-mux-con";
						rockchip,bits = <0x6 0x2>;
						clocks = <0xb 0x8 0xc 0x22>;
						clock-output-names = "aclk_rkvdec";
						#clock-cells = <0x0>;
						#clock-init-cells = <0x1>;
						linux,phandle = <0x3>;
						phandle = <0x3>;
					};

					clk_vdec_cabac_div {
						compatible = "rockchip,rk3188-div-con";
						rockchip,bits = <0x8 0x5>;
						clocks = <0x3a>;
						clock-output-names = "clk_vdec_cabac";
						rockchip,div-type = <0x0>;
						#clock-cells = <0x0>;
						rockchip,clkops-idx = <0x1>;
						rockchip,flags = <0x100>;
					};

					clk_vdec_cabac_mux {
						compatible = "rockchip,rk3188-mux-con";
						rockchip,bits = <0xe 0x2>;
						clocks = <0xb 0x8 0xc 0x22>;
						clock-output-names = "clk_vdec_cabac";
						#clock-cells = <0x0>;
						#clock-init-cells = <0x1>;
						linux,phandle = <0x3a>;
						phandle = <0x3a>;
					};
				};

				sel-con@00b8 {
					compatible = "rockchip,rk3188-selcon";
					reg = <0xb8 0x4>;
					#address-cells = <0x1>;
					#size-cells = <0x1>;

					dclk_hdmiphy_div {
						compatible = "rockchip,rk3188-div-con";
						rockchip,bits = <0x0 0x3>;
						clocks = <0x39>;
						clock-output-names = "dclk_hdmiphy";
						rockchip,div-type = <0x0>;
						#clock-cells = <0x0>;
						rockchip,clkops-idx = <0x1>;
					};

					clk_macphy_div {
						compatible = "rockchip,rk3188-div-con";
						rockchip,bits = <0x8 0x3>;
						clocks = <0x3b>;
						clock-output-names = "clk_macphy";
						rockchip,div-type = <0x0>;
						#clock-cells = <0x0>;
						rockchip,clkops-idx = <0x1>;
					};

					mac_clkin {
						compatible = "rockchip,rk3188-mux-con";
						rockchip,bits = <0xa 0x1>;
						clocks = <0x3c 0x3d>;
						clock-output-names = "mac_clkin";
						#clock-cells = <0x0>;
						#clock-init-cells = <0x1>;
						linux,phandle = <0x18>;
						phandle = <0x18>;
					};

					clk_macphy_mux {
						compatible = "rockchip,rk3188-mux-con";
						rockchip,bits = <0xc 0x1>;
						clocks = <0x3e 0x3c>;
						clock-output-names = "clk_macphy";
						#clock-cells = <0x0>;
						#clock-init-cells = <0x1>;
						linux,phandle = <0x3b>;
						phandle = <0x3b>;
					};
				};

				sel-con@00bc {
					compatible = "rockchip,rk3188-selcon";
					reg = <0xbc 0x4>;
					#address-cells = <0x1>;
					#size-cells = <0x1>;

					i2s2_frac {
						compatible = "rockchip,rk3188-frac-con";
						clocks = <0x2e>;
						clock-output-names = "i2s2_frac";
						rockchip,bits = <0x0 0x20>;
						rockchip,clkops-idx = <0x5>;
						#clock-cells = <0x0>;
						linux,phandle = <0x2f>;
						phandle = <0x2f>;
					};
				};

				sel-con@00c0 {
					compatible = "rockchip,rk3188-selcon";
					reg = <0xc0 0x4>;
					#address-cells = <0x1>;
					#size-cells = <0x1>;

					aclk_iep_div {
						compatible = "rockchip,rk3188-div-con";
						rockchip,bits = <0x0 0x5>;
						clocks = <0xe>;
						clock-output-names = "aclk_iep";
						rockchip,div-type = <0x0>;
						#clock-cells = <0x0>;
						rockchip,clkops-idx = <0x1>;
						rockchip,flags = <0x100>;
					};

					aclk_iep_mux {
						compatible = "rockchip,rk3188-mux-con";
						rockchip,bits = <0x5 0x2>;
						clocks = <0xb 0x8 0xc 0x22>;
						clock-output-names = "aclk_iep";
						#clock-cells = <0x0>;
						#clock-init-cells = <0x1>;
						linux,phandle = <0xe>;
						phandle = <0xe>;
					};

					aclk_hdcp_div {
						compatible = "rockchip,rk3188-div-con";
						rockchip,bits = <0x8 0x5>;
						clocks = <0x3f>;
						clock-output-names = "aclk_hdcp";
						rockchip,div-type = <0x0>;
						#clock-cells = <0x0>;
						rockchip,clkops-idx = <0x1>;
						rockchip,flags = <0x100>;
					};

					aclk_hdcp_mux {
						compatible = "rockchip,rk3188-mux-con";
						rockchip,bits = <0xd 0x2>;
						clocks = <0xb 0x8 0xc 0x22>;
						clock-output-names = "aclk_hdcp";
						#clock-cells = <0x0>;
						linux,phandle = <0x3f>;
						phandle = <0x3f>;
					};
				};

				sel-con@00c4 {
					compatible = "rockchip,rk3188-selcon";
					reg = <0xc4 0x4>;
					#address-cells = <0x1>;
					#size-cells = <0x1>;

					aclk_vpu_div {
						compatible = "rockchip,rk3188-div-con";
						rockchip,bits = <0x0 0x5>;
						clocks = <0x4>;
						clock-output-names = "aclk_vpu";
						rockchip,div-type = <0x0>;
						#clock-cells = <0x0>;
						rockchip,clkops-idx = <0x1>;
						rockchip,flags = <0x100>;
					};

					aclk_vpu_mux {
						compatible = "rockchip,rk3188-mux-con";
						rockchip,bits = <0x5 0x2>;
						clocks = <0xb 0x8 0xc 0x22>;
						clock-output-names = "aclk_vpu";
						#clock-cells = <0x0>;
						#clock-init-cells = <0x1>;
						linux,phandle = <0x4>;
						phandle = <0x4>;
					};
				};

				sel-con@00c8 {
					compatible = "rockchip,rk3188-selcon";
					reg = <0xc8 0x4>;
					#address-cells = <0x1>;
					#size-cells = <0x1>;

					aclk_vop_div {
						compatible = "rockchip,rk3188-div-con";
						rockchip,bits = <0x0 0x5>;
						clocks = <0x40>;
						clock-output-names = "aclk_vop";
						rockchip,div-type = <0x0>;
						#clock-cells = <0x0>;
						rockchip,clkops-idx = <0x1>;
						rockchip,flags = <0x100>;
					};

					aclk_vop_mux {
						compatible = "rockchip,rk3188-mux-con";
						rockchip,bits = <0x5 0x2>;
						clocks = <0xb 0x8 0xc 0x22>;
						clock-output-names = "aclk_vop";
						#clock-cells = <0x0>;
						#clock-init-cells = <0x1>;
						linux,phandle = <0x40>;
						phandle = <0x40>;
					};

					aclk_rga_div {
						compatible = "rockchip,rk3188-div-con";
						rockchip,bits = <0x8 0x5>;
						clocks = <0x31>;
						clock-output-names = "aclk_rga";
						rockchip,div-type = <0x0>;
						#clock-cells = <0x0>;
						rockchip,clkops-idx = <0x1>;
						rockchip,flags = <0x100>;
					};

					aclk_rga_mux {
						compatible = "rockchip,rk3188-mux-con";
						rockchip,bits = <0xd 0x2>;
						clocks = <0xb 0x8 0xc 0x22>;
						clock-output-names = "aclk_rga";
						#clock-cells = <0x0>;
						#clock-init-cells = <0x1>;
						linux,phandle = <0x31>;
						phandle = <0x31>;
					};
				};

				sel-con@00cc {
					compatible = "rockchip,rk3188-selcon";
					reg = <0xcc 0x4>;
					#address-cells = <0x1>;
					#size-cells = <0x1>;

					clk_gpu_div {
						compatible = "rockchip,rk3188-div-con";
						rockchip,bits = <0x0 0x5>;
						clocks = <0x41>;
						clock-output-names = "clk_gpu";
						rockchip,div-type = <0x0>;
						#clock-cells = <0x0>;
						rockchip,clkops-idx = <0x1>;
						rockchip,flags = <0x100>;
					};

					clk_gpu_mux {
						compatible = "rockchip,rk3188-mux-con";
						rockchip,bits = <0x5 0x2>;
						clocks = <0xb 0x8 0xc 0x22>;
						clock-output-names = "clk_gpu";
						#clock-cells = <0x0>;
						#clock-init-cells = <0x1>;
						linux,phandle = <0x41>;
						phandle = <0x41>;
					};

					clk_vdec_core_div {
						compatible = "rockchip,rk3188-div-con";
						rockchip,bits = <0x8 0x5>;
						clocks = <0x42>;
						clock-output-names = "clk_vdec_core";
						rockchip,div-type = <0x0>;
						#clock-cells = <0x0>;
						rockchip,clkops-idx = <0x1>;
						rockchip,flags = <0x100>;
					};

					clk_vdec_core_mux {
						compatible = "rockchip,rk3188-mux-con";
						rockchip,bits = <0xd 0x2>;
						clocks = <0xb 0x8 0xc 0x22>;
						clock-output-names = "clk_vdec_core";
						#clock-cells = <0x0>;
						#clock-init-cells = <0x1>;
						linux,phandle = <0x42>;
						phandle = <0x42>;
					};
				};

				sel-con@0134 {
					compatible = "rockchip,rk3188-selcon";
					reg = <0x134 0x4>;
					#address-cells = <0x1>;
					#size-cells = <0x1>;

					testclk_mux {
						compatible = "rockchip,rk3188-mux-con";
						rockchip,bits = <0x8 0x4>;
						clocks = <0x33 0x38 0x6 0x43 0x0 0xe 0x41 0x20 0x44>;
						clock-output-names = "testclk";
						#clock-cells = <0x0>;
						#clock-init-cells = <0x1>;
						linux,phandle = <0x16>;
						phandle = <0x16>;
					};

					hdmi_phy_clk_mux {
						compatible = "rockchip,rk3188-mux-con";
						rockchip,bits = <0xd 0x1>;
						clocks = <0x45 0x2>;
						clock-output-names = "hdmi_phy_clk";
						#clock-cells = <0x0>;
						#clock-init-cells = <0x1>;
						linux,phandle = <0xc>;
						phandle = <0xc>;
					};

					usb480m_phy_mux {
						compatible = "rockchip,rk3188-mux-con";
						rockchip,bits = <0xe 0x1>;
						clocks = <0x46 0x47>;
						clock-output-names = "usb480m_phy";
						#clock-cells = <0x0>;
						#clock-init-cells = <0x1>;
						linux,phandle = <0x48>;
						phandle = <0x48>;
					};

					usb480m_mux {
						compatible = "rockchip,rk3188-mux-con";
						rockchip,bits = <0xf 0x1>;
						clocks = <0x48 0x2>;
						clock-output-names = "usb480m";
						#clock-cells = <0x0>;
						rockchip,clkops-idx = <0xf>;
						#clock-init-cells = <0x1>;
						linux,phandle = <0x22>;
						phandle = <0x22>;
					};
				};
			};

			clk_gate_cons {
				compatible = "rockchip,rk-gate-cons";
				#address-cells = <0x1>;
				#size-cells = <0x1>;
				ranges;

				gate-clk@00d0 {
					compatible = "rockchip,rk3188-gate-clk";
					reg = <0xd0 0x4>;
					clocks = <0x38 0x38 0x38 0x1e 0x1f 0x49 0x38 0x2d 0x2f 0x4a 0x10 0x12 0x38 0x4b 0x15 0x16>;
					clock-output-names = "reserved", "reserved", "reserved", "clk_i2s0_pll", "i2s0_frac", "clk_i2s0", "reserved", "clk_i2s2_pll", "i2s2_frac", "clk_i2s2", "clk_i2s1_pll", "i2s1_frac", "reserved", "clk_i2s1_out", "clk_i2s1", "testclk";
					#clock-cells = <0x1>;
				};

				gate-clk@00d4 {
					compatible = "rockchip,rk3188-gate-clk";
					reg = <0xd4 0x4>;
					clocks = <0xf 0x40 0x31 0x4c 0x3f 0x2 0x2 0x17 0x25 0x27 0x28 0x2a 0x2b 0x2c 0x38 0x38>;
					clock-output-names = "clk_nandc", "aclk_vop", "aclk_rga", "clk_jtag", "aclk_hdcp", "clk_otgphy0", "clk_otgphy1", "clk_mac_pll", "clk_uart0_pll", "uart0_frac", "clk_uart1_pll", "uart1_frac", "clk_uart2_pll", "uart2_frac", "reserved", "reserved";
					#clock-cells = <0x1>;
					linux,phandle = <0x68>;
					phandle = <0x68>;
				};

				gate-clk@00d8 {
					compatible = "rockchip,rk3188-gate-clk";
					reg = <0xd8 0x4>;
					clocks = <0x38 0x38 0x19 0x38 0x38 0x38 0x32 0x35 0x4d 0x36 0x1a 0x21 0x1c 0x23 0x24 0x33>;
					clock-output-names = "reserved", "clk_ddrmon", "clk_gmac", "reserved", "reserved", "reserved", "clk_tsp", "clk_crypto", "clk_tsadc", "clk_spi0", "clk_spdif_pll", "clk_sdmmc0", "spdif_frac", "clk_sdio", "clk_emmc", "clk_wifi";
					#clock-cells = <0x1>;
					linux,phandle = <0x86>;
					phandle = <0x86>;
				};

				gate-clk@00dc {
					compatible = "rockchip,rk3188-gate-clk";
					reg = <0xdc 0x4>;
					clocks = <0xe 0x38 0x3 0x3a 0x42 0x34 0x31 0x2 0x5 0x38 0x38 0x4 0x38 0x38 0x38 0x38>;
					clock-output-names = "aclk_iep", "dclk_vop0", "aclk_rkvdec", "clk_vdec_cabac", "clk_vdec_core", "clk_hdcp", "clk_rga", "clk_hdmi_hdcp", "clk_hdmi_cec", "reserved", "reserved", "aclk_vpu", "reserved", "clk_gpu", "reserved", "reserved";
					#clock-cells = <0x1>;
					linux,phandle = <0x97>;
					phandle = <0x97>;
				};

				gate-clk@00e0 {
					compatible = "rockchip,rk3188-gate-clk";
					reg = <0xe0 0x4>;
					clocks = <0x6 0x6 0x44 0x38 0x4 0x3 0x38 0x38 0x38 0x38 0x38 0x38 0x38 0x38 0x38 0x38>;
					clock-output-names = "aclk_core", "pclk_dbg", "aclk_gic400", "reserved", "hclk_vpu", "hclk_rkvdec", "reserved", "reserved", "reserved", "reserved", "reserved", "reserved", "reserved", "reserved", "reserved", "reserved";
					#clock-cells = <0x1>;
					linux,phandle = <0x61>;
					phandle = <0x61>;
				};

				gate-clk@00e4 {
					compatible = "rockchip,rk3188-gate-clk";
					reg = <0xe4 0x4>;
					clocks = <0x20 0x20 0x20 0x4e 0x4e 0x4e 0x4e 0x3b 0x38 0x38 0x38 0x38 0x38 0x38 0x38 0x38>;
					clock-output-names = "aclk_peri", "hclk_peri", "pclk_peri", "clk_mac_ref", "clk_mac_refout", "clk_mac_rx", "clk_mac_tx", "clk_macphy", "reserved", "reserved", "reserved", "reserved", "reserved", "reserved", "reserved", "reserved";
					#clock-cells = <0x1>;
					linux,phandle = <0xa8>;
					phandle = <0xa8>;
				};

				gate-clk@00e8 {
					compatible = "rockchip,rk3188-gate-clk";
					reg = <0xe8 0x4>;
					clocks = <0xd 0xd 0xd 0x4f 0x4f 0x2 0x2 0x2 0x2 0x2 0x2 0x38 0x38 0x4f 0x38 0x38>;
					clock-output-names = "aclk_bus", "hclk_bus", "pclk_bus", "pclk_bus_pre", "pclk_phy", "clk_timer0", "clk_timer1", "clk_timer2", "clk_timer3", "clk_timer4", "clk_timer5", "reserved", "reserved", "pclk_ddr", "reserved", "reserved";
					#clock-cells = <0x1>;
					linux,phandle = <0x52>;
					phandle = <0x52>;
				};

				gate-clk@00ec {
					compatible = "rockchip,rk3188-gate-clk";
					reg = <0xec 0x4>;
					clocks = <0x50 0x50 0x38 0x38 0x38 0x38 0x38 0x38 0x38 0x38 0x38 0x38 0x38 0x38 0x38 0x43 0xe>;
					clock-output-names = "clk_ddrphy", "clk4x_ddrphy", "reserved", "reserved", "reserved", "reserved", "reserved", "reserved", "reserved", "reserved", "reserved", "reserved", "reserved", "reserved", "g_aclk_gpu", "g_aclk_gpu_noc";
					#clock-cells = <0x1>;
					linux,phandle = <0x43>;
					phandle = <0x43>;
				};

				gate-clk@00f0 {
					compatible = "rockchip,rk3188-gate-clk";
					reg = <0xf0 0x4>;
					clocks = <0xd 0xd 0xd 0x51 0x52 0xd 0x43 0x0 0x52 0xd 0x51 0x51 0x51 0x51 0x51 0x51 0x4f 0x4f 0x4f>;
					clock-output-names = "g_aclk_intmem", "g_intmem_mbist", "g_aclk_dmac_bus", "g_hclk_rom", "g_p_ddrupctl", "g_clk_ddrupctl", "g_p_ddrmon", "g_h_i2s0_8ch", "g_h_i2s1_8ch", "g_h_i2s2_2ch", "g_h_spdif_8ch", "g_h_crypto_mst", "g_h_crypto_slv", "g_p_efuse_1024", "g_p_efuse_256", "g_pclk_i2c0";
					#clock-cells = <0x1>;
					linux,phandle = <0x62>;
					phandle = <0x62>;
				};

				gate-clk@00f4 {
					compatible = "rockchip,rk3188-gate-clk";
					reg = <0xf4 0x4>;
					clocks = <0x4f 0x4f 0x4f 0x38 0x4f 0x4f 0x4f 0x4f 0x4f 0x4f 0x4f 0x4f 0x4f 0x4f 0x4f 0x4f>;
					clock-output-names = "g_pclk_i2c1", "g_pclk_i2c2", "g_pclk_i2c3", "reserved", "g_pclk_timer0", "g_pclk_stimer", "g_pclk_spi0", "g_pclk_rk_pwm", "g_pclk_gpio0", "g_pclk_gpio1", "g_pclk_gpio2", "g_pclk_gpio3", "g_pclk_uart0", "g_pclk_uart1", "g_pclk_uart2", "g_pclk_tsadc";
					#clock-cells = <0x1>;
					linux,phandle = <0x64>;
					phandle = <0x64>;
				};

				gate-clk@00f8 {
					compatible = "rockchip,rk3188-gate-clk";
					reg = <0xf8 0x4>;
					clocks = <0x4f 0xd 0x52 0xd 0x52 0x4 0x4f 0x52 0x4 0x4f 0x52 0x4 0x52 0x4 0x52 0x4 0x4f 0x51 0x53 0x38 0x38 0x38>;
					clock-output-names = "g_pclk_grf", "g_aclk_bus", "g_p_mschniu", "g_p_ddrphy", "g_pclk_cru", "g_p_acodecphy", "g_pclk_sgrf", "g_p_hdmiphy", "g_p_vdacphy", "g_p_phy_noc", "g_pclk_sim", "g_hclk_tsp", "clk_hsadc_tsp", "reserved", "reserved", "reserved";
					#clock-cells = <0x1>;
					linux,phandle = <0x63>;
					phandle = <0x63>;
				};

				gate-clk@00fc {
					compatible = "rockchip,rk3188-gate-clk";
					reg = <0xfc 0x4>;
					clocks = <0x54 0x54 0x54 0x54 0x20 0x55 0x54 0x54 0x54 0x54 0x54 0x38 0x54 0x54 0x54 0x38>;
					clock-output-names = "g_hclk_sdmmc", "g_hclk_sdio", "g_clk_emmc", "g_clk_nandc", "g_aclk_gmac", "g_pclk_gmac", "g_hclk_host0", "g_h_host0_arb", "g_hclk_host1", "g_h_host1_arb", "g_hclk_host2", "reserved", "g_hclk_otg", "g_hclk_otg_pmu", "g_h_host2_arb", "reserved";
					#clock-cells = <0x1>;
					linux,phandle = <0x66>;
					phandle = <0x66>;
				};

				gate-clk@0100 {
					compatible = "rockchip,rk3188-gate-clk";
					reg = <0x100 0x4>;
					clocks = <0x20 0x54 0x55 0x38 0x38 0x38 0x38 0x38 0x38 0x38 0x38 0x38 0x38 0x38 0x38 0x38>;
					clock-output-names = "g_a_peri_noc", "g_h_peri_noc", "g_p_peri_noc", "reserved", "reserved", "reserved", "reserved", "reserved", "reserved", "reserved", "reserved", "reserved", "reserved", "reserved", "reserved", "reserved";
					#clock-cells = <0x1>;
					linux,phandle = <0x65>;
					phandle = <0x65>;
				};

				gate-clk@0104 {
					compatible = "rockchip,rk3188-gate-clk";
					reg = <0x104 0x4>;
					clocks = <0x56 0xb 0x57 0x56 0x9 0x57 0x38 0x40 0x57 0x56 0x8 0x57 0xe 0x3f 0x31 0x40 0x57 0x38 0x38>;
					clock-output-names = "g_aclk_rga", "g_hclk_rga", "g_aclk_iep", "g_hclk_iep", "reserved", "g_aclk_vop", "g_hclk_vop", "g_h_vio_ahbarbi", "g_h_vio_noc", "g_a_iep_noc", "g_a_hdcp_noc", "g_a_rga_noc", "g_a_vop_noc", "g_h_vop_noc", "reserved", "reserved";
					#clock-cells = <0x1>;
					linux,phandle = <0x56>;
					phandle = <0x56>;
				};

				gate-clk@0108 {
					compatible = "rockchip,rk3188-gate-clk";
					reg = <0x108 0x4>;
					clocks = <0x38 0x38 0x38 0x38 0x38 0x38 0x57 0x57 0x38 0x38 0x3f 0x57 0x57 0x38 0x38 0x38>;
					clock-output-names = "reserved", "reserved", "reserved", "reserved", "reserved", "reserved", "g_p_hdmi_ctrl", "g_h_vio_h2p", "reserved", "reserved", "g_aclk_hdcp", "g_pclk_hdcp", "g_h_hdcp_mmu", "reserved", "reserved", "reserved";
					#clock-cells = <0x1>;
					linux,phandle = <0x67>;
					phandle = <0x67>;
				};

				gate-clk@010c {
					compatible = "rockchip,rk3188-gate-clk";
					reg = <0x10c 0x4>;
					clocks = <0x38 0x38 0x3 0x58 0x59 0x0 0x59 0x1 0x59 0x2 0x59 0x3 0x38 0x38 0x38 0x38 0x38 0x38 0x38 0x38>;
					clock-output-names = "g_aclk_vpu", "g_hclk_vpu", "g_a_rkvdec", "g_h_rkvdec", "g_a_vpu_noc", "g_h_vpu_noc", "g_a_rkvdec_noc", "g_h_rkvdec_noc", "reserved", "reserved", "reserved", "reserved", "reserved", "reserved", "reserved", "reserved";
					#clock-cells = <0x1>;
					linux,phandle = <0x59>;
					phandle = <0x59>;
				};
			};
		};
	};

	dram_timing {
		compatible = "rockchip,dram-timing";
		dram_spd_bin = <0x15>;
		sr_idle = <0x18>;
		pd_idle = <0x20>;
		dram_dll_disb_freq = <0x12c>;
		phy_dll_disb_freq = <0x190>;
		dram_odt_disb_freq = <0x14d>;
		phy_odt_disb_freq = <0x14d>;
		ddr3_drv = <0x2>;
		ddr3_odt = <0x40>;
		lpddr3_drv = <0x1>;
		lpddr3_odt = <0x3>;
		lpddr2_drv = <0x1>;
		phy_ddr3_clk_drv = <0x1c>;
		phy_ddr3_cmd_drv = <0x1c>;
		phy_ddr3_dqs_drv = <0x1c>;
		phy_ddr3_odt = <0x2>;
		phy_lp23_clk_drv = <0x13>;
		phy_lp23_cmd_drv = <0x16>;
		phy_lp23_dqs_drv = <0x16>;
		phy_lp3_odt = <0x2>;
		linux,phandle = <0x5e>;
		phandle = <0x5e>;
	};

	cpus {
		#address-cells = <0x1>;
		#size-cells = <0x0>;

		cpu@0 {
			device_type = "cpu";
			compatible = "arm,cortex-a7";
			reg = <0xf00>;
		};

		cpu@1 {
			device_type = "cpu";
			compatible = "arm,cortex-a7";
			reg = <0xf01>;
		};

		cpu@2 {
			device_type = "cpu";
			compatible = "arm,cortex-a7";
			reg = <0xf02>;
		};

		cpu@3 {
			device_type = "cpu";
			compatible = "arm,cortex-a7";
			reg = <0xf03>;
		};
	};

	psci {
		compatible = "arm,psci";
		method = "smc";
		cpu_suspend = <0x84000001>;
		cpu_off = <0x84000002>;
		cpu_on = <0x84000003>;
	};

	interrupt-controller@32010000 {
		compatible = "arm,cortex-a15-gic";
		interrupt-controller;
		#interrupt-cells = <0x3>;
		#address-cells = <0x0>;
		reg = <0x32011000 0x1000 0x32012000 0x1000>;
		linux,phandle = <0x1>;
		phandle = <0x1>;
	};

	syscon@10140000 {
		compatible = "rockchip,rk322x-sgrf", "rockchip,sgrf", "syscon";
		reg = <0x10140000 0x1000>;
	};

	syscon@11000000 {
		compatible = "rockchip,rk322x-grf", "rockchip,grf", "syscon";
		reg = <0x11000000 0x1000>;
		linux,phandle = <0x5b>;
		phandle = <0x5b>;
	};

	syscon@110e0000 {
		compatible = "rockchip,rk322x-cru", "rockchip,cru", "syscon";
		reg = <0x110e0000 0x1000>;
	};

	syscon@11200000 {
		compatible = "rockchip,rk322x-ddrpctl", "syscon";
		reg = <0x11200000 0x400>;
	};

	syscon@31020000 {
		compatible = "rockchip,rk322x-msch", "rockchip,msch", "syscon";
		reg = <0x31020000 0x3000>;
	};

	arm-pmu {
		compatible = "arm,cortex-a7-pmu";
		interrupts = <0x0 0x4c 0x4 0x0 0x4d 0x4 0x0 0x4e 0x4 0x0 0x4f 0x4>;
	};

	reset@110e0110 {
		compatible = "rockchip,reset";
		reg = <0x110e0110 0x20>;
		rockchip,reset-flag = <0x1>;
		#reset-cells = <0x1>;
		linux,phandle = <0x8f>;
		phandle = <0x8f>;
	};

	timer {
		compatible = "arm,armv7-timer";
		interrupts = <0x1 0xd 0xf04 0x1 0xe 0xf04>;
		clock-frequency = <0x16e3600>;
	};

	timer@110c0000 {
		compatible = "rockchip,timer";
		reg = <0x110c0000 0x20>;
		interrupts = <0x0 0x2b 0x4>;
		rockchip,broadcast = <0x1>;
	};

	fiq-debugger {
		compatible = "rockchip,fiq-debugger";
		rockchip,serial-id = <0x2>;
		rockchip,signal-irq = <0x9f>;
		rockchip,wake-irq = <0x0>;
		rockchip,irq-mode-enable = <0x0>;
		rockchip,baudrate = <0x16e360>;
		pinctrl-names = "default";
		pinctrl-0 = <0x5a>;
		status = "okay";
	};

	io-domains {
		compatible = "rockchip,rk322x-io-voltage-domain";
		rockchip,grf = <0x5b>;
		status = "okay";
		vccio1-supply = <0x5c>;
		vccio2-supply = <0x5d>;
		vccio4-supply = <0x5c>;
	};

	dvfs {

		vd_arm {
			regulator_name = "vdd_arm";

			pd_core {

				clk_core {
					operating-points = <0x639c0 0xe7ef0 0x927c0 0xee098 0xc7380 0xf4240 0xf6180 0x11edd8 0x124f80 0x137478>;
					max-volt = <0x149970>;
					temp-limit-enable = <0x0>;
					target-temp = <0x73>;
					min_temp_limit = <0x927c0>;
					normal-temp-limit = <0x3 0x17700 0x6 0x23280 0x9 0x2ee00 0xf 0x5dc00>;
					performance-temp-limit = <0x6e 0xc7380>;
					status = "okay";
					regu-mode-table = <0xf6180 0x4 0x0 0x3>;
					regu-mode-en = <0x0>;
					lkg_adjust_volt_en = <0x1>;
					channel = <0x0>;
					tsadc-ch = <0x0>;
					def_table_lkg = <0x8>;
					min_adjust_freq = <0xf6180>;
					lkg_adjust_volt_table = <0x14 0xc350 0x3c 0x124f8>;
				};
			};
		};

		vd_logic {
			regulator_name = "vdd_logic";

			pd_ddr {

				clk_ddr {
					operating-points = <0x493e0 0x100590 0x61a80 0x10c8e0 0x88b80 0x118c30>;
					lkg_adjust_volt_en = <0x1>;
					channel = <0x2>;
					def_table_lkg = <0x5>;
					min_adjust_freq = <0x493e0>;
					lkg_adjust_volt_table = <0x7 0xc350 0x3c 0x186a0>;
					temp-limit-enable = <0x1>;
					status = "okay";
					freq-table = <0x1 0x88b80 0x10 0x88b80 0x10000 0x88b80 0x2000 0x88b80>;
				};
			};

			pd_gpu {

				clk_gpu {
					operating-points = <0x30d40 0x100590 0x493e0 0x100590 0x7a120 0x118c30>;
					temp-limit-enable = <0x0>;
					target-temp = <0x73>;
					min_temp_limit = <0x30d40>;
					normal-temp-limit = <0x3 0x186a0>;
					channel = <0x2>;
					status = "okay";
					regu-mode-table = <0x30d40 0x4 0x0 0x3>;
					regu-mode-en = <0x0>;
				};
			};
		};
	};

	rockchip-ion {
		compatible = "rockchip,ion";
		#address-cells = <0x1>;
		#size-cells = <0x0>;

		rockchip,ion-heap@4 {
			compatible = "rockchip,ion-heap";
			rockchip,ion_heap = <0x4>;
			reg = <0x0 0x0>;
		};

		rockchip,ion-heap@5 {
			compatible = "rockchip,ion-heap";
			rockchip,ion_heap = <0x5>;
			reg = <0x0 0x0>;
		};

		system-heap {
			compatible = "rockchip,ion-heap";
			rockchip,ion_heap = <0x0>;
		};
	};

	dram {
		compatible = "rockchip,rk322x-dram";
		status = "okay";
		dram_freq = <0x1dcd6500>;
		rockchip,dram_timing = <0x5e>;
	};

	clocks-init {
		compatible = "rockchip,clocks-init";
		rockchip,clocks-init-parent = <0x1e 0x8 0x10 0x8 0x2d 0x8 0x1a 0x8 0x41 0xb 0x5f 0xc 0x21 0xb 0x24 0xb 0x23 0xb 0x4 0xb 0xc 0x45 0x22 0x48 0x3 0xb>;
		rockchip,clocks-init-rate = <0x8 0x47868c00 0x6 0x29b92700 0xb 0x1d4c0000 0xd 0xee6b280 0x51 0x8f0d180 0x4f 0x47868c0 0x20 0x8f0d180 0x54 0x8f0d180 0x55 0x47868c0 0x4e 0x7735940 0xe 0xee6b280 0x57 0x7735940 0x31 0xee6b280 0x41 0xee6b280 0x4 0x17d7840 0x42 0xee6b280 0x3a 0xee6b280 0x3 0xf42400 0x40 0x17d78400 0x5 0x8000>;
	};

	clocks-enable {
		compatible = "rockchip,clocks-enable";
		clocks = <0x7 0x9 0x8 0xb 0x6 0x60 0x44 0x61 0x2 0x52 0x3 0x43 0x1 0x62 0x5 0x62 0x0 0x62 0x1 0x62 0x2 0x63 0x1 0x62 0x3 0x62 0x4 0x62 0x6 0x64 0x4 0x64 0x5 0x64 0x8 0x63 0x0 0x63 0x4 0x63 0x6 0x63 0x3 0x63 0x9 0x63 0x2 0x65 0x0 0x65 0x1 0x65 0x2 0x66 0xd 0x56 0x7 0x67 0x7 0x52 0x5 0x52 0x6 0x59 0x4 0x59 0x6 0x59 0x5 0x59 0x7 0x56 0xb 0x43 0xf 0x56 0x9 0x56 0xc 0x56 0xa 0x56 0x8 0x56 0xd 0x5 0x68 0x3>;
	};

	serial@11010000 {
		compatible = "rockchip,serial";
		reg = <0x11010000 0x100>;
		interrupts = <0x0 0x37 0x4>;
		clock-frequency = <0x16e3600>;
		clocks = <0x69 0x64 0xc>;
		clock-names = "sclk_uart", "pclk_uart";
		reg-shift = <0x2>;
		reg-io-width = <0x4>;
		dmas = <0x6a 0x2 0x6a 0x3>;
		#dma-cells = <0x2>;
		pinctrl-names = "default";
		pinctrl-0 = <0x6b 0x6c 0x6d>;
		status = "disabled";
	};

	serial@11020000 {
		compatible = "rockchip,serial";
		reg = <0x11020000 0x100>;
		interrupts = <0x0 0x38 0x4>;
		clock-frequency = <0x16e3600>;
		clocks = <0x6e 0x64 0xd>;
		clock-names = "sclk_uart", "pclk_uart";
		reg-shift = <0x2>;
		reg-io-width = <0x4>;
		dmas = <0x6a 0x4 0x6a 0x5>;
		#dma-cells = <0x2>;
		pinctrl-names = "default";
		pinctrl-0 = <0x6f 0x70 0x71>;
		status = "okay";
		dma-names = "!tx", "!rx";
	};

	serial@11030000 {
		compatible = "rockchip,serial";
		reg = <0x11030000 0x100>;
		interrupts = <0x0 0x39 0x4>;
		clock-frequency = <0x16e3600>;
		clocks = <0x72 0x64 0xe>;
		clock-names = "sclk_uart", "pclk_uart";
		reg-shift = <0x2>;
		reg-io-width = <0x4>;
		dmas = <0x6a 0x6 0x6a 0x7>;
		#dma-cells = <0x2>;
		pinctrl-names = "default";
		pinctrl-0 = <0x5a>;
		status = "disabled";
	};

	i2c@11050000 {
		compatible = "rockchip,rk30-i2c";
		reg = <0x11050000 0x1000>;
		interrupts = <0x0 0x24 0x4>;
		#address-cells = <0x1>;
		#size-cells = <0x0>;
		pinctrl-names = "default", "gpio", "sleep";
		pinctrl-0 = <0x73>;
		pinctrl-1 = <0x74>;
		pinctrl-2 = <0x75>;
		gpios = <0x76 0x1 0x1 0x76 0x0 0x1>;
		clocks = <0x62 0xf>;
		rockchip,check-idle = <0x1>;
		status = "disabled";
	};

	i2c@11060000 {
		compatible = "rockchip,rk30-i2c";
		reg = <0x11060000 0x1000>;
		interrupts = <0x0 0x25 0x4>;
		#address-cells = <0x1>;
		#size-cells = <0x0>;
		pinctrl-names = "default", "gpio", "sleep";
		pinctrl-0 = <0x77>;
		pinctrl-1 = <0x78>;
		pinctrl-2 = <0x79>;
		gpios = <0x76 0x3 0x1 0x76 0x2 0x1>;
		clocks = <0x64 0x0>;
		rockchip,check-idle = <0x1>;
		status = "disabled";

		nau8540@1c {
			compatible = "nuvoton,nau8540";
			reg = <0x1c>;
			linux,phandle = <0xbf>;
			phandle = <0xbf>;
		};

		nau8540@1d {
			compatible = "nuvoton,nau8540";
			reg = <0x1d>;
		};
	};

	i2c@11070000 {
		compatible = "rockchip,rk30-i2c";
		reg = <0x11070000 0x1000>;
		interrupts = <0x0 0x26 0x4>;
		#address-cells = <0x1>;
		#size-cells = <0x0>;
		pinctrl-names = "default", "gpio", "sleep";
		pinctrl-0 = <0x7a>;
		pinctrl-1 = <0x7b>;
		pinctrl-2 = <0x7c>;
		gpios = <0x7d 0x14 0x1 0x7d 0x15 0x1>;
		clocks = <0x64 0x1>;
		rockchip,check-idle = <0x1>;
		status = "disabled";
	};

	i2c@11080000 {
		compatible = "rockchip,rk30-i2c";
		reg = <0x11080000 0x1000>;
		interrupts = <0x0 0x27 0x4>;
		#address-cells = <0x1>;
		#size-cells = <0x0>;
		pinctrl-names = "default", "gpio", "sleep";
		pinctrl-0 = <0x7e>;
		pinctrl-1 = <0x7f>;
		pinctrl-2 = <0x80>;
		gpios = <0x76 0x7 0x1 0x76 0x6 0x1>;
		clocks = <0x64 0x2>;
		rockchip,check-idle = <0x1>;
		status = "disabled";
	};

	spi@11090000 {
		compatible = "rockchip,rockchip-spi";
		reg = <0x11090000 0x1000>;
		interrupts = <0x0 0x31 0x4>;
		#address-cells = <0x1>;
		#size-cells = <0x0>;
		pinctrl-names = "default";
		pinctrl-0 = <0x81 0x82 0x83 0x84 0x85>;
		rockchip,spi-src-clk = <0x0>;
		num-cs = <0x2>;
		clocks = <0x86 0x9 0x64 0x6>;
		clock-names = "spi", "pclk_spi0";
		status = "disabled";
		max-freq = <0x2dc6c00>;

		spi_test@00 {
			compatible = "rockchip,spi_test_bus0_cs0";
			reg = <0x0>;
			spi-max-frequency = <0xb71b00>;
			poll_mode = <0x0>;
			type = <0x0>;
		};

		spi_test@01 {
			compatible = "rockchip,spi_test_bus0_cs1";
			reg = <0x1>;
			spi-max-frequency = <0xb71b00>;
			spi-cpha;
			spi-cpol;
			poll_mode = <0x0>;
			type = <0x0>;
		};
	};

	wdt@110a0000 {
		compatible = "rockchip,watch dog";
		reg = <0x110a0000 0x100>;
		clocks = <0x52 0x3>;
		clock-names = "pclk_wdt";
		interrupts = <0x0 0x28 0x4>;
		rockchip,irq = <0x1>;
		rockchip,timeout = <0x3c>;
		rockchip,atboot = <0x1>;
		rockchip,debug = <0x0>;
		status = "disabled";
	};

	amba {
		#address-cells = <0x1>;
		#size-cells = <0x1>;
		compatible = "arm,amba-bus";
		interrupt-parent = <0x1>;
		ranges;

		pdma@110f0000 {
			compatible = "arm,pl330", "arm,primecell";
			reg = <0x110f0000 0x4000>;
			clocks = <0x62 0x2>;
			clock-names = "apb_pclk";
			interrupts = <0x0 0x0 0x4 0x0 0x1 0x4>;
			#dma-cells = <0x1>;
			linux,phandle = <0x6a>;
			phandle = <0x6a>;
		};
	};

	crypto@100a0000 {
		compatible = "rockchip-crypto";
		reg = <0x100a0000 0x10000>;
		interrupts = <0x0 0x1e 0x4>;
		interrupt-names = "irq_crypto";
		clocks = <0x35 0x62 0xc 0x62 0xb>;
		clock-names = "clk_crypto", "hclk_crypto", "aclk_crypto";
		status = "disabled";
	};

	i2s0@100c0000 {
		compatible = "rockchip-i2s";
		reg = <0x100c0000 0x1000>;
		i2s-id = <0x0>;
		clocks = <0x49 0x62 0x7>;
		clock-names = "i2s_clk", "i2s_hclk";
		interrupts = <0x0 0x1a 0x4>;
		dmas = <0x6a 0xb 0x6a 0xc>;
		#dma-cells = <0x2>;
		dma-names = "tx", "rx";
		status = "okay";
		linux,phandle = <0xbe>;
		phandle = <0xbe>;
	};

	i2s1@100b0000 {
		compatible = "rockchip-i2s";
		reg = <0x100b0000 0x1000>;
		i2s-id = <0x1>;
		clocks = <0x15 0x4b 0x62 0x8>;
		clock-names = "i2s_clk", "i2s_mclk", "i2s_hclk";
		interrupts = <0x0 0x1b 0x4>;
		dmas = <0x6a 0xe 0x6a 0xf>;
		#dma-cells = <0x2>;
		dma-names = "tx", "rx";
		status = "okay";
		linux,phandle = <0xba>;
		phandle = <0xba>;
	};

	i2s2@100e0000 {
		compatible = "rockchip-i2s";
		reg = <0x100e0000 0x1000>;
		i2s-id = <0x2>;
		clocks = <0x4a 0x62 0x9>;
		clock-names = "i2s_clk", "i2s_hclk";
		interrupts = <0x0 0x1c 0x4>;
		dmas = <0x6a 0x0 0x6a 0x1>;
		#dma-cells = <0x2>;
		dma-names = "tx", "rx";
		pinctrl-names = "default", "sleep";
		pinctrl-0 = <0x87 0x88 0x89 0x8a>;
		pinctrl-1 = <0x8b>;
		status = "disabled";
	};

	spdif@100d0000 {
		compatible = "rockchip-spdif";
		reg = <0x100d0000 0x1000>;
		clocks = <0x8c 0x62 0xa>;
		clock-names = "spdif_mclk", "spdif_hclk";
		interrupts = <0x0 0x1d 0x4>;
		dmas = <0x6a 0xa>;
		#dma-cells = <0x1>;
		dma-names = "tx";
		pinctrl-names = "default";
		pinctrl-0 = <0x8d>;
		status = "okay";
		linux,phandle = <0xbc>;
		phandle = <0xbc>;
	};

	codec@12010000 {
		compatible = "rockchip,rk322x-codec";
		reg = <0x12010000 0x1000>;
		clocks = <0x63 0x5>;
		clock-names = "g_pclk_acodec";
		spk_ctl_io = <0x8e 0x5 0x0>;
		status = "okay";
		spk_depop_time = <0x64>;
		linux,phandle = <0xb9>;
		phandle = <0xb9>;
	};

	codec-spdif {
		compatible = "hdmi-spdif";
		status = "okay";
		linux,phandle = <0xbb>;
		phandle = <0xbb>;
	};

	codec-hdmi-i2s {
		compatible = "hdmi-i2s";
		status = "okay";
		linux,phandle = <0xbd>;
		phandle = <0xbd>;
	};

	tsadc@11150000 {
		compatible = "rockchip,rk322x-tsadc";
		reg = <0x11150000 0x100>;
		interrupts = <0x0 0x3a 0x4>;
		clock-frequency = <0x8000>;
		clocks = <0x4d 0x64 0xf>;
		clock-names = "tsadc", "pclk_tsadc";
		resets = <0x8f 0x57>;
		reset-names = "tsadc-apb";
		#io-channel-cells = <0x1>;
		io-channel-ranges;
		pinctrl-names = "default";
		pinctrl-0 = <0x90>;
		tsadc-ht-temp = <0x78>;
		tsadc-ht-reset-cru = <0x1>;
		tsadc-ht-pull-gpio = <0x0>;
		status = "okay";
	};

	gpu {
		compatible = "arm,mali400";
		reg = <0x20001000 0x200 0x20000000 0x100 0x20003000 0x100 0x20008000 0x1100 0x20004000 0x100 0x2000a000 0x1100 0x20005000 0x100>;
		reg-names = "Mali_L2", "Mali_GP", "Mali_GP_MMU", "Mali_PP0", "Mali_PP0_MMU", "Mali_PP1", "Mali_PP1_MMU";
		interrupts = <0x0 0x6 0x4 0x0 0x5 0x4 0x0 0x4 0x4 0x0 0x5 0x4 0x0 0x4 0x4 0x0 0x5 0x4>;
		interrupt-names = "Mali_GP_IRQ", "Mali_GP_MMU_IRQ", "Mali_PP0_IRQ", "Mali_PP0_MMU_IRQ", "Mali_PP1_IRQ", "Mali_PP1_MMU_IRQ";
	};

	fb {
		compatible = "rockchip,rk-fb";
		rockchip,disp-mode = <0x0>;
		rockchip,disp-policy = <0x1>;
		rockchip,uboot-logo-on = <0x1>;
	};

	rk_screen {
		compatible = "rockchip,screen";
		display-timings = <0x91>;
	};

	pwm@110b0000 {
		compatible = "rockchip,rk-pwm";
		reg = <0x110b0000 0x10>;
		interrupts = <0x0 0x32 0x4>;
		#pwm-cells = <0x2>;
		pinctrl-names = "default";
		pinctrl-0 = <0x92>;
		clocks = <0x64 0x7>;
		clock-names = "pclk_pwm";
		status = "disabled";
	};

	pwm@110b0010 {
		compatible = "rockchip,rk-pwm";
		reg = <0x110b0010 0x10>;
		interrupts = <0x0 0x32 0x4>;
		#pwm-cells = <0x2>;
		pinctrl-names = "default";
		pinctrl-0 = <0x93>;
		clocks = <0x64 0x7>;
		clock-names = "pclk_pwm";
		status = "okay";
		linux,phandle = <0xb7>;
		phandle = <0xb7>;
	};

	pwm@110b0020 {
		compatible = "rockchip,rk-pwm";
		reg = <0x110b0020 0x10>;
		interrupts = <0x0 0x32 0x4>;
		#pwm-cells = <0x2>;
		pinctrl-names = "default";
		pinctrl-0 = <0x94>;
		clocks = <0x64 0x7>;
		clock-names = "pclk_pwm";
		status = "okay";
		linux,phandle = <0xb8>;
		phandle = <0xb8>;
	};

	pwm@110b0030 {
		compatible = "rockchip,remotectl-pwm";
		reg = <0x110b0030 0x10>;
		interrupts = <0x0 0x32 0x4>;
		#pwm-cells = <0x2>;
		pinctrl-names = "default";
		pinctrl-0 = <0x95>;
		clocks = <0x64 0x7>;
		clock-names = "pclk_pwm";
		status = "okay";
		remote_pwm_id = <0x3>;
		handle_cpu_id = <0x1>;

		ir_key1 {
			rockchip,usercode = <0x4040>;
			rockchip,key_table = <0xb2 0x74 0xbc 0x71 0xac 0xff 0xa4 0x100 0xa8 0x96 0xab 0xfa 0xe3 0x72 0xe1 0x19c 0xe0 0x197 0xea 0x73 0xe5 0x66 0xf4 0x67 0xbd 0x9e 0xef 0x69 0xf2 0xe8 0xee 0x6a 0xba 0x8b 0xf1 0x6c 0xbb 0x184 0xfe 0x2 0xfd 0x3 0xfc 0x4 0xfb 0x5 0xfa 0x6 0xf9 0x7 0xf8 0x8 0xf7 0x9 0xf6 0xa 0xf0 0x0 0xff 0xb 0xf3 0x6f 0xd0 0xfa 0xd1 0xfb>;
		};

		ir_key2 {
			rockchip,usercode = <0xfe01>;
			rockchip,key_table = <0xbf 0x74 0xbe 0x71 0xef 0x72 0xe7 0x73 0xee 0x66 0xe9 0x67 0xe6 0x9e 0xae 0x69 0xec 0xe8 0xaf 0x6a 0xb3 0x8b 0xe5 0x6c 0xff 0x184 0xb1 0x2 0xf2 0x3 0xf3 0x4 0xb5 0x5 0xf6 0x6 0xf7 0x7 0xb9 0x8 0xfa 0x9 0xfb 0xa 0xfe 0xb 0xbd 0x6f 0xf0 0xfa 0xbc 0xfb>;
		};

		ir_key3 {
			rockchip,usercode = <0x1dcc>;
			rockchip,key_table = <0xe 0x74 0xfe 0x71 0xf6 0x19c 0xd9 0xa4 0xdc 0x73 0xf5 0x197 0xe5 0x66 0xdd 0x72 0xfd 0x8b 0xfa 0x67 0xfc 0x9e 0xf8 0x69 0xfb 0xe8 0xf7 0x6a 0xef 0xb 0xf9 0x6c 0xe4 0x0 0xee 0x2 0xed 0x3 0xec 0x4 0xeb 0x5 0xea 0x6 0xe9 0x7 0xe8 0x8 0xe7 0x9 0xe6 0xa>;
		};

		ir_key4 {
			rockchip,usercode = <0xdf00>;
			rockchip,key_table = <0xe3 0x74 0xbe 0x96 0xa0 0xf9 0xfe 0x100 0xa3 0x72 0xb4 0x19c 0xb0 0x197 0xa2 0x73 0xbd 0x66 0xe5 0x67 0xf5 0x9e 0xb8 0x69 0xf9 0xe8 0xf8 0x6a 0xe7 0x8b 0xb7 0x6c 0xfc 0x184 0xab 0x2 0xe9 0x3 0xea 0x4 0xaf 0x5 0xed 0x6 0xee 0x7 0xb3 0x8 0xf1 0x9 0xf2 0xa 0xf3 0xb 0xef 0x6f>;
		};

		ir_key5 {
			rockchip,usercode = <0xdf20>;
			rockchip,key_table = <0xa5 0x104 0xae 0x105 0xa9 0x106>;
		};

		ir_key6 {
			rockchip,usercode = <0xff00>;
			rockchip,key_table = <0xb8 0x104 0xba 0x105 0xb9 0x106>;
		};

		ir_key7 {
			rockchip,usercode = <0x7f80>;
			rockchip,key_table = <0x7e 0x74 0x7c 0x8b 0x8c 0x66 0xc7 0x67 0xbf 0x6c 0xc8 0x69 0xc6 0x6a 0xec 0xe8 0xd8 0x9e 0x76 0x72 0x78 0x73 0xb7 0x184>;
		};
	};

	vpu_service@20020000 {
		compatible = "vpu_service";
		rockchip,grf = <0x5b>;
		iommu_enabled = <0x1>;
		reg = <0x20020000 0x800>;
		interrupts = <0x0 0x9 0x4 0x0 0xb 0x4>;
		interrupt-names = "irq_dec", "irq_enc";
		clocks = <0x4 0x96>;
		clock-names = "aclk_vcodec", "hclk_vcodec";
		resets = <0x8f 0x71 0x8f 0x70>;
		reset-names = "video_h", "video_a";
		dev_mode = <0x0>;
		status = "okay";
	};

	rkvdec@20030000 {
		compatible = "rockchip,rkvdec";
		rockchip,grf = <0x5b>;
		iommu_enabled = <0x1>;
		reg = <0x20030000 0x400>;
		interrupts = <0x0 0x7 0x4>;
		interrupt-names = "irq_dec";
		clocks = <0x3 0x58 0x3a 0x42>;
		clock-names = "aclk_vcodec", "hclk_vcodec", "clk_cabac", "clk_core";
		resets = <0x8f 0x78 0x8f 0x76>;
		reset-names = "video_h", "video_a";
		dev_mode = <0x2>;
		status = "okay";
	};

	vop@20050000 {
		compatible = "rockchip,rk322x-lcdc";
		rockchip,prop = <0x1>;
		rockchip,cabc_mode = <0x0>;
		rockchip,pwr18 = <0x0>;
		rockchip,iommu-enabled = <0x1>;
		reg = <0x20050000 0x2000>;
		interrupts = <0x0 0x20 0x4>;
		clocks = <0x56 0x5 0x5f 0x56 0x6 0x56 0xc 0x56 0xd>;
		clock-names = "aclk_vop", "dclk_vop", "hclk_vop", "aclk_vop_noc", "hclk_vop_noc";
	};

	rga@20060000 {
		compatible = "rockchip,rga2";
		reg = <0x20060000 0x1000>;
		interrupts = <0x0 0x21 0x4>;
		clocks = <0x56 0x0 0x56 0x1 0x31>;
		clock-names = "aclk_rga", "hclk_rga", "pd_rga";
	};

	iep@20070000 {
		compatible = "rockchip,iep";
		iommu_enabled = <0x1>;
		reg = <0x20070000 0x800>;
		interrupts = <0x0 0x1f 0x4>;
		clocks = <0x56 0x2 0x56 0x3>;
		clock-names = "aclk_iep", "hclk_iep";
		version = <0x3>;
		status = "okay";
	};

	vop_mmu {
		dbgname = "vop";
		compatible = "rockchip,vop_mmu";
		reg = <0x20053f00 0x100>;
		interrupts = <0x0 0x20 0x4>;
		interrupt-names = "vop_mmu";
	};

	vpu_mmu {
		dbgname = "vpu";
		compatible = "rockchip,vpu_mmu";
		reg = <0x20020800 0x100>;
		interrupts = <0x0 0xa 0x4>;
		interrupt-names = "vpu_mmu";
	};

	iep_mmu {
		dbgname = "iep";
		compatible = "rockchip,iep_mmu";
		reg = <0x20070800 0x100>;
		interrupts = <0x0 0x1f 0x4>;
		interrupt-names = "iep_mmu";
	};

	vdec_mmu {
		dbgname = "vdec";
		compatible = "rockchip,vdec_mmu";
		reg = <0x20030480 0x40 0x200304c0 0x40>;
		interrupts = <0x0 0x8 0x4>;
		interrupt-names = "vdec_mmu";
	};

	hdmi@200a0000 {
		compatible = "rockchip,rk322x-hdmi";
		reg = <0x200a0000 0x20000 0x12030000 0x10000>;
		interrupts = <0x0 0x23 0x4 0x0 0x47 0x4>;
		clocks = <0x97 0x7 0x67 0x6 0x63 0x7 0x5>;
		clock-names = "hdcp_clk_hdmi", "pclk_hdmi", "pclk_hdmi_phy", "cec_clk_hdmi";
		pinctrl-names = "default", "gpio";
		pinctrl-0 = <0x98 0x99 0x9a>;
		pinctrl-1 = <0x7f 0x98>;
		resets = <0x8f 0x60>;
		reset-names = "hdmi";
		rockchip,grf = <0x5b>;
		rockchip,hdmi_audio_source = <0x0>;
		rockchip,hdcp_enable = <0x0>;
		rockchip,cec_enable = <0x1>;
		status = "okay";
		rockchip,phy_table = <0x9d5b340 0x0 0x0 0x4 0x4 0x4 0x4 0xd693a40 0x0 0x0 0x6 0x6 0x6 0x6 0x1443fd00 0x1 0x0 0x6 0xa 0xa 0xa 0x2367b880 0x1 0x0 0x7 0xa 0xa 0xa>;
	};

	hdmi_hdcp2@20090000 {
		compatible = "rockchip,rk322x-hdmi-hdcp2";
		reg = <0x20090000 0x10000>;
		interrupts = <0x0 0x22 0x4>;
		clocks = <0x56 0xa 0x67 0xc 0x67 0xb 0x67 0xa 0x34>;
		clock-names = "aclk_noc_hdcp2", "hclk_hdcp2_mmu", "pclk_hdcp2", "aclk_hdcp2", "hdcp2_clk_hdmi";
		status = "disabled";
	};

	tve {
		compatible = "rockchip,rk322x-tve";
		reg = <0x20053e00 0x100 0x12020000 0x10000>;
		clocks = <0x63 0x8>;
		clock-names = "pclk_vdac";
		saturation = <0x305b46>;
		brightcontrast = <0x9900>;
		adjtiming = <0xd6c00880>;
		lumafilter0 = <0x2ff0001>;
		lumafilter1 = <0xf40200fe>;
		lumafilter2 = <0xf332d910>;
		daclevel = <0x15>;
		dac1level = <0x7>;
		status = "okay";
	};

	rksdmmc@30020000 {
		compatible = "rockchip,rk_mmc", "rockchip,rk322x-sdmmc";
		reg = <0x30020000 0x10000>;
		interrupts = <0x0 0xe 0x4>;
		#address-cells = <0x1>;
		#size-cells = <0x0>;
		clocks = <0x24 0x66 0x2>;
		clock-names = "clk_mmc", "hclk_mmc";
		num-slots = <0x1>;
		fifo-depth = <0x100>;
		bus-width = <0x8>;
		tune_regsbase = <0x1d8>;
		resets = <0x8f 0x53>;
		reset-names = "mmc_ahb_reset";
		clock-frequency = <0x5f5e100>;
		clock-freq-min-max = <0x61a80 0x5f5e100>;
		supports-highspeed;
		supports-emmc;
		bootpart-no-access;
		ignore-pm-notify;
		keep-power-in-suspend;
		status = "okay";
	};

	rksdmmc@30000000 {
		compatible = "rockchip,rk_mmc", "rockchip,rk322x-sdmmc";
		reg = <0x30000000 0x10000>;
		interrupts = <0x0 0xc 0x4>;
		#address-cells = <0x1>;
		#size-cells = <0x0>;
		pinctrl-names = "default", "idle";
		pinctrl-0 = <0x9b 0x9c 0x9d 0x9e 0x9f>;
		pinctrl-1 = <0xa0>;
		cd-gpios = <0x8e 0x11 0x0>;
		clocks = <0x21 0x66 0x0>;
		clock-names = "clk_mmc", "hclk_mmc";
		num-slots = <0x1>;
		fifo-depth = <0x100>;
		bus-width = <0x4>;
		resets = <0x8f 0x51>;
		reset-names = "mmc_ahb_reset";
		clock-frequency = <0x23c3460>;
		clock-freq-min-max = <0x61a80 0x23c3460>;
		supports-highspeed;
		supports-sd;
		broken-cd;
		card-detect-delay = <0xc8>;
		ignore-pm-notify;
		keep-power-in-suspend;
		power-inverted;
		status = "okay";
	};

	rksdmmc@30010000 {
		compatible = "rockchip,rk_mmc", "rockchip,rk322x-sdmmc";
		reg = <0x30010000 0x10000>;
		interrupts = <0x0 0xd 0x4>;
		#address-cells = <0x1>;
		#size-cells = <0x0>;
		pinctrl-names = "default", "idle";
		pinctrl-0 = <0xa1 0xa2 0xa3>;
		pinctrl-1 = <0xa4>;
		clocks = <0x23 0x66 0x1>;
		clock-names = "clk_mmc", "hclk_mmc";
		num-slots = <0x1>;
		fifo-depth = <0x100>;
		bus-width = <0x4>;
		tune_regsbase = <0x1c8>;
		resets = <0x8f 0x52>;
		reset-names = "mmc_ahb_reset";
		clock-frequency = <0x23c3460>;
		clock-freq-min-max = <0x30d40 0x23c3460>;
		supports-highspeed;
		supports-sdio;
		ignore-pm-notify;
		keep-power-in-suspend;
		cap-sdio-irq;
		status = "okay";
	};

	nandc@30030000 {
		compatible = "rockchip,rk-nandc";
		reg = <0x30030000 0x4000>;
		interrupts = <0x0 0xf 0x4>;
		nandc_id = <0x0>;
		clocks = <0xf 0x68 0x0 0x66 0x3>;
		clock-names = "clk_nandc", "g_clk_nandc", "hclk_nandc";
		status = "okay";
	};

	phy {
		compatible = "rockchip,rk322x-usb-phy";
		rockchip,grf = <0x5b>;
		#address-cells = <0x1>;
		#size-cells = <0x0>;

		usb-phy0 {
			#phy-cells = <0x0>;
			reg = <0x764>;
			linux,phandle = <0xa5>;
			phandle = <0xa5>;
		};

		usb-phy1 {
			#phy-cells = <0x0>;
			reg = <0x800>;
			linux,phandle = <0xa6>;
			phandle = <0xa6>;
		};

		usb-phy2 {
			#phy-cells = <0x0>;
			reg = <0x804>;
			linux,phandle = <0xa7>;
			phandle = <0xa7>;
		};
	};

	otg@30040000 {
		compatible = "rockchip,rk322x_usb20_otg";
		reg = <0x30040000 0x40000>;
		interrupts = <0x0 0x17 0x4>;
		clocks = <0x68 0x5 0x66 0xc 0x66 0xd>;
		clock-names = "clk_usbphy0", "hclk_otg", "hclk_otg_pmu";
		resets = <0x8f 0x45 0x8f 0x67 0x8f 0x46>;
		reset-names = "otg_ahb", "otg_phy", "otg_controller";
		rockchip,usb-mode = <0x0>;
	};

	ehci0@30080000 {
		compatible = "generic-ehci";
		reg = <0x30080000 0x20000>;
		interrupts = <0x0 0x10 0x4>;
		clocks = <0x68 0x5 0x66 0x6 0x66 0x7>;
		clock-names = "clk_usbphy0", "hclk_host0", "hclk_host0_arb";
		phys = <0xa5>;
		phy-names = "usb";
		resets = <0x8f 0x47 0x8f 0x68 0x8f 0x48>;
		reset-names = "host_ahb", "host_phy", "host_controller";
	};

	ohci0@300a0000 {
		compatible = "generic-ohci";
		reg = <0x300a0000 0x20000>;
		interrupts = <0x0 0x11 0x4>;
	};

	ehci1@300c0000 {
		compatible = "generic-ehci";
		reg = <0x300c0000 0x20000>;
		interrupts = <0x0 0x13 0x4>;
		clocks = <0x68 0x6 0x66 0x8 0x66 0x9>;
		clock-names = "clk_usbphy1", "hclk_host1", "hclk_host1_arb";
		phys = <0xa6>;
		phy-names = "usb";
		resets = <0x8f 0x49 0x8f 0x69 0x8f 0x4a>;
		reset-names = "host_ahb", "host_phy", "host_controller";
	};

	ohci1@300e0000 {
		compatible = "generic-ohci";
		reg = <0x300e0000 0x20000>;
		interrupts = <0x0 0x14 0x4>;
	};

	ehci2@30100000 {
		compatible = "generic-ehci";
		reg = <0x30100000 0x20000>;
		interrupts = <0x0 0x42 0x4>;
		clocks = <0x68 0x6 0x66 0xa 0x66 0xe>;
		clock-names = "clk_usbphy1", "hclk_host2", "hck_host2_arb";
		phys = <0xa7>;
		phy-names = "usb";
		resets = <0x8f 0x4b 0x8f 0x6a 0x8f 0x4c>;
		reset-names = "host_ahb", "host_phy", "host_controller";
	};

	ohci2@30120000 {
		compatible = "generic-ohci";
		reg = <0x30120000 0x20000>;
		interrupts = <0x0 0x43 0x4>;
	};

	eth@30200000 {
		compatible = "rockchip,rk322x-gmac";
		reg = <0x30200000 0x10000>;
		rockchip,grf = <0x5b>;
		interrupts = <0x0 0x18 0x4>;
		interrupt-names = "macirq";
		clocks = <0x4e 0xa8 0x5 0xa8 0x6 0xa8 0x3 0xa8 0x4 0x66 0x4 0x66 0x5>;
		clock-names = "clk_mac", "mac_clk_rx", "mac_clk_tx", "clk_mac_ref", "clk_mac_refout", "aclk_mac", "pclk_mac";
		resets = <0x8f 0x3f>;
		reset-names = "mac-phy";
		phy-mode = "rmii";
		pinctrl-names = "default";
		pinctrl-0 = <0xa9>;
		status = "okay";
		link-gpio = <0x7d 0xe 0x0>;
		led-gpio = <0x7d 0x8 0x0>;
		clock_in_out = "output";
		tx_delay = <0x26>;
		rx_delay = <0x11>;
		phy-type = "internal";
	};

	rockchip_suspend {
		rockchip,ctrbits = <0x11806>;
	};

	pinctrl {
		compatible = "rockchip,rk322x-pinctrl";
		rockchip,grf = <0x5b>;
		#address-cells = <0x1>;
		#size-cells = <0x1>;
		ranges;

		gpio0@11110000 {
			compatible = "rockchip,gpio-bank";
			reg = <0x11110000 0x100>;
			interrupts = <0x0 0x33 0x4>;
			clocks = <0x64 0x9>;
			gpio-controller;
			#gpio-cells = <0x2>;
			interrupt-controller;
			#interrupt-cells = <0x2>;
			linux,phandle = <0x76>;
			phandle = <0x76>;
		};

		gpio1@11120000 {
			compatible = "rockchip,gpio-bank";
			reg = <0x11120000 0x100>;
			interrupts = <0x0 0x34 0x4>;
			clocks = <0x64 0x9>;
			gpio-controller;
			#gpio-cells = <0x2>;
			interrupt-controller;
			#interrupt-cells = <0x2>;
			linux,phandle = <0x8e>;
			phandle = <0x8e>;
		};

		gpio2@11130000 {
			compatible = "rockchip,gpio-bank";
			reg = <0x11130000 0x100>;
			interrupts = <0x0 0x35 0x4>;
			clocks = <0x64 0xa>;
			gpio-controller;
			#gpio-cells = <0x2>;
			interrupt-controller;
			#interrupt-cells = <0x2>;
			linux,phandle = <0x7d>;
			phandle = <0x7d>;
		};

		gpio3@11140000 {
			compatible = "rockchip,gpio-bank";
			reg = <0x11140000 0x100>;
			interrupts = <0x0 0x36 0x4>;
			clocks = <0x64 0xb>;
			gpio-controller;
			#gpio-cells = <0x2>;
			interrupt-controller;
			#interrupt-cells = <0x2>;
			linux,phandle = <0xb4>;
			phandle = <0xb4>;
		};

		pcfg-pull-up {
			bias-pull-up;
			linux,phandle = <0xac>;
			phandle = <0xac>;
		};

		pcfg-pull-down {
			bias-pull-down;
			linux,phandle = <0xb2>;
			phandle = <0xb2>;
		};

		pcfg-pull-none {
			bias-disable;
			linux,phandle = <0xaa>;
			phandle = <0xaa>;
		};

		pcfg-pull-none-drv-8ma {
			drive-strength = <0x8>;
			linux,phandle = <0xaf>;
			phandle = <0xaf>;
		};

		pcfg-pull-none-drv-12ma {
			drive-strength = <0xc>;
			linux,phandle = <0xb1>;
			phandle = <0xb1>;
		};

		pcfg-pull-up-drv-8ma {
			bias-pull-up;
			drive-strength = <0x8>;
			linux,phandle = <0xb0>;
			phandle = <0xb0>;
		};

		pcfg-pull-none-drv-4ma {
			drive-strength = <0x4>;
			linux,phandle = <0xad>;
			phandle = <0xad>;
		};

		pcfg-pull-up-drv-4ma {
			bias-pull-up;
			drive-strength = <0x4>;
			linux,phandle = <0xae>;
			phandle = <0xae>;
		};

		pcfg-pull-down-drv-12ma {
			bias-pull-down;
			drive-strength = <0xc>;
		};

		pcfg-output-high {
			output-high;
		};

		pcfg-output-low {
			output-low;
		};

		pcfg-input-high {
			bias-pull-up;
			input-enable;
			linux,phandle = <0xab>;
			phandle = <0xab>;
		};

		i2c0 {

			i2c0-xfer {
				rockchip,pins = <0x0 0x0 0x1 0xaa 0x0 0x1 0x1 0xaa>;
				linux,phandle = <0x73>;
				phandle = <0x73>;
			};

			i2c0-gpio {
				rockchip,pins = <0x0 0x0 0x0 0xaa 0x0 0x1 0x0 0xaa>;
				linux,phandle = <0x74>;
				phandle = <0x74>;
			};

			i2c0-sleep {
				rockchip,pins = <0x0 0x0 0x0 0xab 0x0 0x1 0x0 0xab>;
				linux,phandle = <0x75>;
				phandle = <0x75>;
			};
		};

		i2c1 {

			i2c1-xfer {
				rockchip,pins = <0x0 0x2 0x1 0xaa 0x0 0x3 0x1 0xaa>;
				linux,phandle = <0x77>;
				phandle = <0x77>;
			};

			i2c1-gpio {
				rockchip,pins = <0x0 0x2 0x0 0xaa 0x0 0x3 0x0 0xaa>;
				linux,phandle = <0x78>;
				phandle = <0x78>;
			};

			i2c1-sleep {
				rockchip,pins = <0x0 0x2 0x0 0xab 0x0 0x3 0x0 0xab>;
				linux,phandle = <0x79>;
				phandle = <0x79>;
			};
		};

		i2c2 {

			i2c2-xfer {
				rockchip,pins = <0x2 0x15 0x1 0xaa 0x2 0x14 0x1 0xaa>;
				linux,phandle = <0x7a>;
				phandle = <0x7a>;
			};

			i2c2-gpio {
				rockchip,pins = <0x2 0x15 0x0 0xaa 0x2 0x14 0x0 0xaa>;
				linux,phandle = <0x7b>;
				phandle = <0x7b>;
			};

			i2c2-sleep {
				rockchip,pins = <0x2 0x15 0x0 0xab 0x2 0x14 0x0 0xab>;
				linux,phandle = <0x7c>;
				phandle = <0x7c>;
			};
		};

		i2c3 {

			i2c3-xfer {
				rockchip,pins = <0x0 0x6 0x1 0xaa 0x0 0x7 0x1 0xaa>;
				linux,phandle = <0x7e>;
				phandle = <0x7e>;
			};

			i2c3-gpio {
				rockchip,pins = <0x0 0x6 0x0 0xaa 0x0 0x7 0x0 0xaa>;
				linux,phandle = <0x7f>;
				phandle = <0x7f>;
			};

			i2c3-sleep {
				rockchip,pins = <0x0 0x6 0x0 0xab 0x0 0x7 0x0 0xab>;
				linux,phandle = <0x80>;
				phandle = <0x80>;
			};
		};

		uart0 {

			uart0-xfer {
				rockchip,pins = <0x2 0x1a 0x1 0xac 0x2 0x1b 0x1 0xaa>;
				linux,phandle = <0x6b>;
				phandle = <0x6b>;
			};

			uart0-cts {
				rockchip,pins = <0x2 0x1d 0x1 0xaa>;
				linux,phandle = <0x6c>;
				phandle = <0x6c>;
			};

			uart0-rts {
				rockchip,pins = <0x0 0x11 0x1 0xaa>;
				linux,phandle = <0x6d>;
				phandle = <0x6d>;
			};

			uart0-rts-gpio {
				rockchip,pins = <0x0 0x11 0x0 0xaa>;
			};
		};

		uart1-0 {

			uart1-xfer {
				rockchip,pins = <0x1 0xa 0x1 0xac 0x1 0x9 0x1 0xaa>;
			};

			uart1-cts {
				rockchip,pins = <0x1 0x8 0x1 0xaa>;
			};

			uart1-rts {
				rockchip,pins = <0x1 0xb 0x1 0xaa>;
			};

			uart1-rts-gpio {
				rockchip,pins = <0x1 0xb 0x0 0xaa>;
			};
		};

		uart1-1 {

			uart11-xfer {
				rockchip,pins = <0x3 0xe 0x1 0xac 0x3 0xd 0x1 0xaa>;
				linux,phandle = <0x6f>;
				phandle = <0x6f>;
			};

			uart11-cts {
				rockchip,pins = <0x3 0x7 0x1 0xaa>;
				linux,phandle = <0x70>;
				phandle = <0x70>;
			};

			uart11-rts {
				rockchip,pins = <0x3 0x6 0x1 0xaa>;
				linux,phandle = <0xb5>;
				phandle = <0xb5>;
			};

			uart11-rts-gpio {
				rockchip,pins = <0x3 0x6 0x0 0xaa>;
				linux,phandle = <0xb6>;
				phandle = <0xb6>;
			};
		};

		uart2-0 {

			uart2-xfer {
				rockchip,pins = <0x1 0x12 0x2 0xac 0x1 0x13 0x2 0xaa>;
			};

			uart2-cts {
				rockchip,pins = <0x0 0x19 0x1 0xaa>;
			};

			uart2-rts {
				rockchip,pins = <0x0 0x18 0x1 0xaa>;
			};
		};

		uart2-1 {

			uart21-xfer {
				rockchip,pins = <0x1 0xa 0x2 0xac 0x1 0x9 0x2 0xaa>;
				linux,phandle = <0x5a>;
				phandle = <0x5a>;
			};
		};

		spi-0 {

			spi0-clk {
				rockchip,pins = <0x0 0x9 0x2 0xac>;
				linux,phandle = <0x81>;
				phandle = <0x81>;
			};

			spi0-cs0 {
				rockchip,pins = <0x0 0xe 0x2 0xac>;
				linux,phandle = <0x84>;
				phandle = <0x84>;
			};

			spi0-tx {
				rockchip,pins = <0x0 0xb 0x2 0xac>;
				linux,phandle = <0x82>;
				phandle = <0x82>;
			};

			spi0-rx {
				rockchip,pins = <0x0 0xd 0x2 0xac>;
				linux,phandle = <0x83>;
				phandle = <0x83>;
			};

			spi0-cs1 {
				rockchip,pins = <0x1 0xc 0x1 0xac>;
				linux,phandle = <0x85>;
				phandle = <0x85>;
			};
		};

		spi-1 {

			spi1-clk {
				rockchip,pins = <0x0 0x17 0x2 0xac>;
			};

			spi1-cs0 {
				rockchip,pins = <0x2 0x2 0x2 0xac>;
			};

			spi1-rx {
				rockchip,pins = <0x2 0x0 0x2 0xac>;
			};

			spi1-tx {
				rockchip,pins = <0x2 0x1 0x2 0xac>;
			};

			spi1-cs1 {
				rockchip,pins = <0x2 0x3 0x2 0xac>;
			};
		};

		i2s {

			i2s-mclk {
				rockchip,pins = <0x0 0x8 0x1 0xaa>;
			};

			i2s-sclk {
				rockchip,pins = <0x0 0x9 0x1 0xaa>;
			};

			i2s-lrckrx {
				rockchip,pins = <0x0 0xb 0x1 0xaa>;
			};

			i2s-lrcktx {
				rockchip,pins = <0x0 0xc 0x1 0xaa>;
			};

			i2s-sdi {
				rockchip,pins = <0x0 0xe 0x1 0xaa>;
			};

			i2s-sdo0 {
				rockchip,pins = <0x0 0xd 0x1 0xaa>;
			};

			i2s-sdo1 {
				rockchip,pins = <0x1 0x2 0x2 0xaa>;
			};

			i2s-sdo2 {
				rockchip,pins = <0x1 0x4 0x2 0xaa>;
			};

			i2s-sdo3 {
				rockchip,pins = <0x1 0x5 0x2 0xaa>;
			};

			i2s-sleep {
				rockchip,pins = <0x0 0x8 0x0 0xab 0x0 0x9 0x0 0xab 0x0 0xb 0x0 0xab 0x0 0xc 0x0 0xab 0x0 0xe 0x0 0xab 0x0 0xd 0x0 0xab 0x1 0x2 0x0 0xab 0x1 0x4 0x0 0xab 0x1 0x5 0x0 0xab>;
			};
		};

		pcm {

			pcm-rx {
				rockchip,pins = <0x0 0x1a 0x2 0xaa>;
				linux,phandle = <0x87>;
				phandle = <0x87>;
			};

			pcm-tx {
				rockchip,pins = <0x0 0x1b 0x2 0xaa>;
				linux,phandle = <0x88>;
				phandle = <0x88>;
			};

			pcm-clk {
				rockchip,pins = <0x3 0xb 0x1 0xaa>;
				linux,phandle = <0x89>;
				phandle = <0x89>;
			};

			pcm-sync {
				rockchip,pins = <0x3 0xc 0x1 0xaa>;
				linux,phandle = <0x8a>;
				phandle = <0x8a>;
			};

			pcm-sleep {
				rockchip,pins = <0x0 0x1a 0x0 0xab 0x0 0x1b 0x0 0xab 0x3 0xb 0x0 0xab 0x3 0xc 0x0 0xab>;
				linux,phandle = <0x8b>;
				phandle = <0x8b>;
			};
		};

		spdif0 {

			spdif0-tx {
				rockchip,pins = <0x3 0x1b 0x1 0xaa>;
			};
		};

		spdif1 {

			spdif1-tx {
				rockchip,pins = <0x3 0x1f 0x2 0xaa>;
				linux,phandle = <0x8d>;
				phandle = <0x8d>;
			};
		};

		sdmmc {

			sdmmc-clk {
				rockchip,pins = <0x1 0x10 0x1 0xad>;
				linux,phandle = <0x9b>;
				phandle = <0x9b>;
			};

			sdmmc-cmd {
				rockchip,pins = <0x1 0xf 0x1 0xae>;
				linux,phandle = <0x9c>;
				phandle = <0x9c>;
			};

			sdmmc-dectn {
				rockchip,pins = <0x1 0x11 0x1 0xae>;
				linux,phandle = <0x9d>;
				phandle = <0x9d>;
			};

			sdmmc-wrprt {
				rockchip,pins = <0x1 0x7 0x1 0xae>;
			};

			sdmmc-pwren {
				rockchip,pins = <0x1 0xe 0x1 0xae>;
				linux,phandle = <0x9f>;
				phandle = <0x9f>;
			};

			sdmmc-bus1 {
				rockchip,pins = <0x1 0x12 0x1 0xae>;
			};

			sdmmc-bus4 {
				rockchip,pins = <0x1 0x12 0x1 0xae 0x1 0x13 0x1 0xae 0x1 0x14 0x1 0xae 0x1 0x15 0x1 0xae>;
				linux,phandle = <0x9e>;
				phandle = <0x9e>;
			};

			sdmmc-gpio {
				rockchip,pins = <0x1 0x10 0x0 0xae 0x1 0xf 0x0 0xae 0x1 0x11 0x0 0xae 0x1 0x7 0x0 0xae 0x1 0xe 0x0 0xae 0x1 0x12 0x0 0xae 0x1 0x13 0x0 0xae 0x1 0x14 0x0 0xae 0x1 0x15 0x0 0xae>;
				linux,phandle = <0xa0>;
				phandle = <0xa0>;
			};
		};

		sdio-0 {

			sdio-bus1 {
				rockchip,pins = <0x1 0x1 0x1 0xae>;
			};

			sdio-bus4 {
				rockchip,pins = <0x1 0x1 0x1 0xae 0x1 0x2 0x1 0xae 0x1 0x4 0x1 0xae 0x1 0x5 0x1 0xae>;
			};

			sdio-cmd {
				rockchip,pins = <0x0 0x3 0x2 0xae>;
			};

			sdio-clk {
				rockchip,pins = <0x1 0x0 0x1 0xad>;
			};

			sdio-pwren {
				rockchip,pins = <0x0 0x1e 0x1 0xac>;
			};

			sdio-gpio {
				rockchip,pins = <0x0 0x3 0x0 0xae 0x1 0x0 0x0 0xae 0x0 0x1e 0x0 0xae 0x1 0x1 0x0 0xae 0x1 0x2 0x0 0xae 0x1 0x3 0x0 0xae 0x1 0x4 0x0 0xae>;
			};
		};

		sdio-1 {

			sdio1-bus1 {
				rockchip,pins = <0x3 0x2 0x1 0xae>;
			};

			sdio1-bus4 {
				rockchip,pins = <0x3 0x2 0x1 0xae 0x3 0x3 0x1 0xae 0x3 0x4 0x1 0xae 0x3 0x5 0x1 0xae>;
				linux,phandle = <0xa3>;
				phandle = <0xa3>;
			};

			sdio1-cmd {
				rockchip,pins = <0x3 0x1 0x1 0xae>;
				linux,phandle = <0xa1>;
				phandle = <0xa1>;
			};

			sdio1-clk {
				rockchip,pins = <0x3 0x0 0x1 0xad>;
				linux,phandle = <0xa2>;
				phandle = <0xa2>;
			};

			clk-32k-out {
				rockchip,pins = <0x1 0x8 0x2 0xaa>;
				linux,phandle = <0x71>;
				phandle = <0x71>;
			};

			sdio1-gpio {
				rockchip,pins = <0x3 0x3 0x0 0xae 0x3 0x0 0x0 0xae 0x3 0x1 0x0 0xae 0x3 0x2 0x0 0xae 0x3 0x3 0x0 0xae 0x3 0x4 0x0 0xae>;
				linux,phandle = <0xa4>;
				phandle = <0xa4>;
			};
		};

		emmc-0 {

			emmc-clk {
				rockchip,pins = <0x2 0x7 0x2 0xaf>;
			};

			emmc-cmd {
				rockchip,pins = <0x1 0x16 0x2 0xb0>;
			};

			emmc-pwren {
				rockchip,pins = <0x2 0x5 0x2 0xaa>;
			};

			emmc_rstnout {
				rockchip,pins = <0x1 0x17 0x2 0xaa>;
			};

			emmc-bus1 {
				rockchip,pins = <0x1 0x18 0x2 0xb0>;
			};

			emmc-bus4 {
				rockchip,pins = <0x1 0x18 0x2 0xb0 0x1 0x19 0x2 0xb0 0x1 0x1a 0x2 0xb0 0x1 0x1b 0x2 0xb0>;
			};

			emmc-bus8 {
				rockchip,pins = <0x1 0x18 0x2 0xb0 0x1 0x19 0x2 0xb0 0x1 0x1a 0x2 0xb0 0x1 0x1b 0x2 0xb0 0x1 0x1c 0x2 0xb0 0x1 0x1d 0x2 0xb0 0x1 0x1e 0x2 0xb0 0x1 0x1f 0x2 0xb0>;
			};
		};

		emmc-1 {

			emmc1-clk {
				rockchip,pins = <0x2 0x7 0x2 0xaf>;
			};

			emmc1-cmd {
				rockchip,pins = <0x2 0x4 0x2 0xb0>;
			};

			emmc1-pwren {
				rockchip,pins = <0x2 0x5 0x2 0xaa>;
			};

			emmc1_rstnout {
				rockchip,pins = <0x1 0x17 0x2 0xaa>;
			};

			emmc1-bus1 {
				rockchip,pins = <0x1 0x18 0x2 0xb0>;
			};

			emmc1-bus4 {
				rockchip,pins = <0x1 0x18 0x2 0xb0 0x1 0x19 0x2 0xb0 0x1 0x1a 0x2 0xb0 0x1 0x1b 0x2 0xb0>;
			};

			emmc1-bus8 {
				rockchip,pins = <0x1 0x18 0x2 0xb0 0x1 0x19 0x2 0xb0 0x1 0x1a 0x2 0xb0 0x1 0x1b 0x2 0xb0 0x1 0x1c 0x2 0xb0 0x1 0x1d 0x2 0xb0 0x1 0x1e 0x2 0xb0 0x1 0x1f 0x2 0xb0>;
			};
		};

		pwm0-0 {

			pwm0-pin {
				rockchip,pins = <0x0 0x1a 0x1 0xaa>;
			};
		};

		pwm0-1 {

			pwm01-pin {
				rockchip,pins = <0x3 0x15 0x1 0xaa>;
				linux,phandle = <0x92>;
				phandle = <0x92>;
			};
		};

		pwm1-0 {

			pwm1-pin {
				rockchip,pins = <0x0 0x1b 0x1 0xaa>;
			};
		};

		pwm1-1 {

			pwm11-pin {
				rockchip,pins = <0x0 0x1e 0x2 0xaa>;
				linux,phandle = <0x93>;
				phandle = <0x93>;
			};
		};

		pwm2-0 {

			pwm2-pin {
				rockchip,pins = <0x0 0x1c 0x1 0xaa>;
			};
		};

		pwm2-1 {

			pwm21-pin {
				rockchip,pins = <0x1 0xc 0x2 0xaa>;
				linux,phandle = <0x94>;
				phandle = <0x94>;
			};
		};

		pwmir-0 {

			pwmir-pin {
				rockchip,pins = <0x3 0x1a 0x1 0xaa>;
			};
		};

		pwmir-1 {

			pwmir1-pin {
				rockchip,pins = <0x1 0xb 0x2 0xaa>;
				linux,phandle = <0x95>;
				phandle = <0x95>;
			};
		};

		gmac {

			rgmii-pins {
				rockchip,pins = <0x2 0xe 0x1 0xaa 0x2 0xc 0x1 0xaa 0x2 0x19 0x1 0xaa 0x2 0x13 0x1 0xb1 0x2 0x12 0x1 0xb1 0x2 0x16 0x1 0xb1 0x2 0x17 0x1 0xb1 0x2 0x9 0x1 0xb1 0x2 0xd 0x1 0xb1 0x2 0x11 0x1 0xaa 0x2 0x10 0x1 0xaa 0x2 0x15 0x2 0xaa 0x2 0x14 0x2 0xaa 0x2 0xb 0x1 0xaa 0x2 0x8 0x1 0xaa>;
			};

			rmii-pins {
				rockchip,pins = <0x2 0xe 0x1 0xaa 0x2 0xc 0x1 0xaa 0x2 0x19 0x1 0xaa 0x2 0x13 0x1 0xb1 0x2 0x12 0x1 0xb1 0x2 0xd 0x1 0xb1 0x2 0x11 0x1 0xaa 0x2 0x10 0x1 0xaa 0x2 0x8 0x1 0xaa 0x2 0xf 0x1 0xaa>;
			};

			phy-pins {
				rockchip,pins = <0x2 0xe 0x2 0xaa 0x2 0x8 0x2 0xaa>;
				linux,phandle = <0xa9>;
				phandle = <0xa9>;
			};
		};

		tsadc_pin {

			tsadc-int {
				rockchip,pins = <0x0 0x18 0x2 0xaa>;
			};

			tsadc-gpio {
				rockchip,pins = <0x0 0x18 0x0 0xaa>;
				linux,phandle = <0x90>;
				phandle = <0x90>;
			};
		};

		hdmi_pin {

			hdmi-cec {
				rockchip,pins = <0x0 0x14 0x1 0xaa>;
				linux,phandle = <0x98>;
				phandle = <0x98>;
			};

			hdmi-hpd {
				rockchip,pins = <0x0 0xf 0x1 0xb2>;
				linux,phandle = <0x9a>;
				phandle = <0x9a>;
			};
		};

		hdmi_i2c {

			hdmii2c-xfer {
				rockchip,pins = <0x0 0x6 0x2 0xaa 0x0 0x7 0x2 0xaa>;
				linux,phandle = <0x99>;
				phandle = <0x99>;
			};
		};
	};

	power_ctr {
	};

	display-timings {
		native-mode = <0xb3>;
		linux,phandle = <0x91>;
		phandle = <0x91>;

		timing0 {
			screen-type = <0x1>;
			out-face = <0x0>;
			color-mode = <0x2>;
			clock-frequency = <0x46cf710>;
			hactive = <0x500>;
			vactive = <0x2d0>;
			hback-porch = <0xdc>;
			hfront-porch = <0x6e>;
			vback-porch = <0x14>;
			vfront-porch = <0x5>;
			hsync-len = <0x28>;
			vsync-len = <0x5>;
			hsync-active = <0x1>;
			vsync-active = <0x1>;
			de-active = <0x0>;
			pixelclk-active = <0x0>;
			swap-rb = <0x0>;
			swap-rg = <0x0>;
			swap-gb = <0x0>;
			linux,phandle = <0xb3>;
			phandle = <0xb3>;
		};

		timing1 {
			screen-type = <0x1>;
			out-face = <0x0>;
			color-mode = <0x2>;
			clock-frequency = <0x8d9ee20>;
			hactive = <0x780>;
			vactive = <0x438>;
			hback-porch = <0x94>;
			hfront-porch = <0x58>;
			vback-porch = <0x24>;
			vfront-porch = <0x4>;
			hsync-len = <0x2c>;
			vsync-len = <0x5>;
			hsync-active = <0x1>;
			vsync-active = <0x1>;
			de-active = <0x0>;
			pixelclk-active = <0x0>;
			swap-rb = <0x0>;
			swap-rg = <0x0>;
			swap-gb = <0x0>;
		};

		timing2 {
			screen-type = <0x1>;
			out-face = <0x0>;
			color-mode = <0x2>;
			clock-frequency = <0x11b3dc40>;
			hactive = <0xf00>;
			vactive = <0x870>;
			hback-porch = <0x128>;
			hfront-porch = <0xb0>;
			vback-porch = <0x48>;
			vfront-porch = <0x8>;
			hsync-len = <0x58>;
			vsync-len = <0xa>;
			hsync-active = <0x1>;
			vsync-active = <0x1>;
			de-active = <0x0>;
			pixelclk-active = <0x0>;
			swap-rb = <0x0>;
			swap-rg = <0x0>;
			swap-gb = <0x0>;
		};

		timing3 {
			screen-type = <0x5>;
			out-face = <0x0>;
			color-mode = <0x2>;
			clock-frequency = <0x19bfcc0>;
			hactive = <0x2d0>;
			vactive = <0x1e0>;
			hback-porch = <0x2b>;
			hfront-porch = <0x21>;
			vback-porch = <0x13>;
			vfront-porch = <0x0>;
			hsync-len = <0x3e>;
			vsync-len = <0x3>;
			hsync-active = <0x1>;
			vsync-active = <0x1>;
			de-active = <0x0>;
			pixelclk-active = <0x1>;
			swap-rb = <0x0>;
			swap-rg = <0x0>;
			swap-gb = <0x0>;
			interlaced;
		};

		timing4 {
			screen-type = <0x5>;
			out-face = <0x0>;
			color-mode = <0x2>;
			clock-frequency = <0x19bfcc0>;
			hactive = <0x2d0>;
			vactive = <0x240>;
			hback-porch = <0x30>;
			hfront-porch = <0x21>;
			vback-porch = <0x13>;
			vfront-porch = <0x2>;
			hsync-len = <0x3f>;
			vsync-len = <0x3>;
			hsync-active = <0x1>;
			vsync-active = <0x1>;
			de-active = <0x0>;
			pixelclk-active = <0x1>;
			swap-rb = <0x0>;
			swap-rg = <0x0>;
			swap-gb = <0x0>;
			interlaced;
		};
	};

	wireless-wlan {
		compatible = "wlan-platdata";
		wifi_chip_type = "ap6330";
		sdio_vref = <0x708>;
		WIFI,poweren_gpio = <0x7d 0x1a 0x0>;
		WIFI,host_wake_irq = <0x76 0x1c 0x0>;
		status = "okay";
	};

	wireless-bluetooth {
		compatible = "bluetooth-platdata";
		uart_rts_gpios = <0xb4 0x6 0x1>;
		pinctrl-names = "default", "rts_gpio";
		pinctrl-0 = <0xb5>;
		pinctrl-1 = <0xb6>;
		BT,power_gpio = <0x7d 0x1d 0x0>;
		BT,wake_gpio = <0xb4 0x1b 0x0>;
		BT,wake_host_irq = <0xb4 0x1a 0x0>;
		status = "okay";
		LED,blue_gpio = <0x8e 0x7 0x1>;
		LED,red_gpio = <0xb4 0x15 0x1>;
	};

	regulators {
		compatible = "simple-bus";
		#address-cells = <0x1>;
		#size-cells = <0x0>;

		regulator@0 {
			compatible = "regulator-fixed";
			regulator-name = "vccio_1v8";
			regulator-min-microvolt = <0x1b7740>;
			regulator-max-microvolt = <0x1b7740>;
			regulator-always-on;
			linux,phandle = <0x5d>;
			phandle = <0x5d>;
		};

		regulator@1 {
			compatible = "regulator-fixed";
			regulator-name = "vccio_3v3";
			regulator-min-microvolt = <0x325aa0>;
			regulator-max-microvolt = <0x325aa0>;
			regulator-always-on;
			linux,phandle = <0x5c>;
			phandle = <0x5c>;
		};
	};

	pwm-regulator1 {
		compatible = "rockchip_pwm_regulator";
		pwms = <0xb7 0x0 0x1388>;
		rockchip,pwm_id = <0x1>;
		rockchip,pwm_voltage_map = <0xe7ef0 0xee098 0xf4240 0xfa3e8 0x100590 0x106738 0x10c8e0 0x112a88 0x118c30 0x11edd8 0x124f80 0x12b128 0x1312d0 0x137478 0x13d620 0x1437c8 0x149970 0x14fb18 0x155cc0>;
		rockchip,pwm_voltage = <0x10c8e0>;
		rockchip,pwm_min_voltage = <0xe7ef0>;
		rockchip,pwm_max_voltage = <0x155cc0>;
		rockchip,pwm_suspend_voltage = <0xe7ef0>;
		rockchip,pwm_coefficient = <0x1c2>;
		status = "okay";

		regulators {
			#address-cells = <0x1>;
			#size-cells = <0x0>;

			regulator@0 {
				regulator-compatible = "pwm_dcdc1";
				regulator-name = "vdd_arm";
				regulator-min-microvolt = <0xe7ef0>;
				regulator-max-microvolt = <0x155cc0>;
				regulator-always-on;
				regulator-boot-on;
			};
		};
	};

	pwm-regulator2 {
		compatible = "rockchip_pwm_regulator";
		pwms = <0xb8 0x0 0x1388>;
		rockchip,pwm_id = <0x2>;
		rockchip,pwm_voltage_map = <0xf4240 0xfa3e8 0x100590 0x106738 0x10c8e0 0x112a88 0x118c30 0x11edd8 0x124f80 0x12b128 0x1312d0 0x137478 0x13d620>;
		rockchip,pwm_voltage = <0x124f80>;
		rockchip,pwm_min_voltage = <0xf4240>;
		rockchip,pwm_max_voltage = <0x13d620>;
		rockchip,pwm_suspend_voltage = <0x1312d0>;
		rockchip,pwm_coefficient = <0x12c>;
		status = "okay";

		regulators {
			#address-cells = <0x1>;
			#size-cells = <0x0>;

			regulator@1 {
				regulator-compatible = "pwm_dcdc2";
				regulator-name = "vdd_logic";
				regulator-min-microvolt = <0xf4240>;
				regulator-max-microvolt = <0x13d620>;
				regulator-always-on;
				regulator-boot-on;
			};
		};
	};

	usb_control {
		compatible = "rockchip,rk322x-usb-control";
		rockchip,remote_wakeup;
		rockchip,usb_irq_wakeup;
		host_drv_gpio = <0xb4 0x14 0x1>;
		otg_drv_gpio = <0xb4 0x16 0x1>;
	};

	rockchip_audio {
		compatible = "rockchip,rk322x-audio";

		dais {

			dai0 {
				audio-codec = <0xb9>;
				audio-controller = <0xba>;
				format = "i2s";
			};
		};
	};

	rockchip_spdif_card {
		compatible = "rockchip-spdif-card";

		dais {

			dai0 {
				audio-codec = <0xbb>;
				audio-controller = <0xbc>;
			};
		};
	};

	rockchip_hdmi_i2s {
		compatible = "rockchip-hdmi-i2s";

		dais {

			dai0 {
				audio-codec = <0xbd>;
				audio-controller = <0xbe>;
				format = "i2s";
			};
		};
	};

	rockchip_nau8540 {
		status = "disabled";
		compatible = "rockchip,nau8540-audio";

		dais {

			dai0 {
				audio-codec = <0xbf>;
				audio-controller = <0xba>;
				format = "i2s";
			};
		};
	};

	status-led {
		compatible = "cyx,leds";
		LED,red_gpio = <0xb4 0x15 0x1>;
		LED,blue_gpio = <0x8e 0x7 0x1>;
		gpio_id0 = <0x76 0xe 0x1>;
		gpio_id1 = <0x76 0xd 0x1>;
		gpio_id2 = <0x8e 0x3 0x1>;
		status = "okay";
	};

	shutdown-key {
		compatible = "cyx,shutdown_key";
		shutdown_key_io = <0x76 0x3 0x1>;
		status = "okay";
	};

	cyx-vfd {
		compatible = "cyxtech,vfd";
		dev_name = "cyx-vfd";
		vfd,clock_gpio = <0x8e 0x0 0x1>;
		vfd,stb_gpio = <0x8e 0x1 0x1>;
		vfd,data_gpio = <0x8e 0x2 0x1>;
		status = "okay";
	};
};
